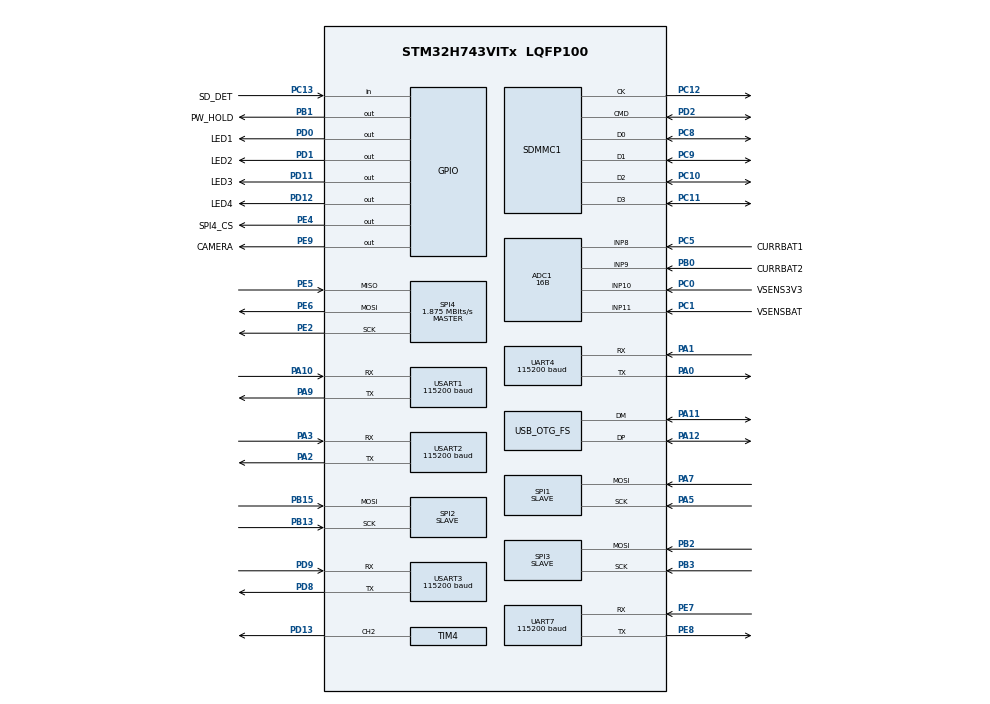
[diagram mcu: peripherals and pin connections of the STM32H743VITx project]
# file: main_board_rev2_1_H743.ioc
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ADC1.Channel-0\#ChannelRegularConversion=ADC_CHANNEL_8
ADC1.Channel-1\#ChannelRegularConversion=ADC_CHANNEL_9
ADC1.Channel-2\#ChannelRegularConversion=ADC_CHANNEL_10
ADC1.Channel-3\#ChannelRegularConversion=ADC_CHANNEL_11
ADC1.Channel-IN10=ADC_CHANNEL_10
ADC1.Channel-IN11=ADC_CHANNEL_11
ADC1.Channel-IN8=ADC_CHANNEL_8
ADC1.Channel-IN9=ADC_CHANNEL_9
ADC1.ClockPrescaler=ADC_CLOCK_ASYNC_DIV8
ADC1.ContinuousConvMode=ENABLE
ADC1.ConversionDataManagement=ADC_CONVERSIONDATA_DMA_CIRCULAR
ADC1.DiscontinuousConvMode=DISABLE
ADC1.EOCSelection=ADC_EOC_SINGLE_CONV
ADC1.EnableAnalogWatchDog1=false
ADC1.EnableAnalogWatchDog2=false
ADC1.EnableAnalogWatchDog3=false
ADC1.EnableInjectedConversion=DISABLE
ADC1.EnableRegularConversion=ENABLE
ADC1.ExternalTrigConv=ADC_SOFTWARE_START
ADC1.ExternalTrigConvEdge=ADC_EXTERNALTRIGCONVEDGE_NONE
ADC1.LeftBitShift=ADC_LEFTBITSHIFT_NONE
ADC1.LowPowerAutoWait=DISABLE
ADC1.Mode=ADC_MODE_INDEPENDENT
ADC1.NbrOfConversion=4
ADC1.OffsetNumber-0\#ChannelRegularConversion=ADC_OFFSET_NONE
ADC1.OffsetNumber-1\#ChannelRegularConversion=ADC_OFFSET_NONE
ADC1.OffsetNumber-2\#ChannelRegularConversion=ADC_OFFSET_NONE
ADC1.OffsetNumber-3\#ChannelRegularConversion=ADC_OFFSET_NONE
ADC1.OffsetSignedSaturation-0\#ChannelRegularConversion=DISABLE
ADC1.OffsetSignedSaturation-1\#ChannelRegularConversion=DISABLE
ADC1.OffsetSignedSaturation-2\#ChannelRegularConversion=DISABLE
ADC1.OffsetSignedSaturation-3\#ChannelRegularConversion=DISABLE
ADC1.Overrun=ADC_OVR_DATA_PRESERVED
ADC1.OversamplingMode=DISABLE
ADC1.Rank-0\#ChannelRegularConversion=1
ADC1.Rank-1\#ChannelRegularConversion=2
ADC1.Rank-2\#ChannelRegularConversion=3
ADC1.Rank-3\#ChannelRegularConversion=4
ADC1.Resolution=ADC_RESOLUTION_16B
ADC1.SamplingTime-0\#ChannelRegularConversion=ADC_SAMPLETIME_387CYCLES_5
ADC1.SamplingTime-1\#ChannelRegularConversion=ADC_SAMPLETIME_387CYCLES_5
ADC1.SamplingTime-2\#ChannelRegularConversion=ADC_SAMPLETIME_387CYCLES_5
ADC1.SamplingTime-3\#ChannelRegularConversion=ADC_SAMPLETIME_387CYCLES_5
ADC1.ScanConvMode=ADC_SCAN_ENABLE
ADC1.master=1
CORTEX_M7.CPU_DCache=Disabled
CORTEX_M7.CPU_ICache=Enabled
CORTEX_M7.MPU_Control=__NULL
Dma.ADC1.4.Direction=DMA_PERIPH_TO_MEMORY
Dma.ADC1.4.EventEnable=DISABLE
Dma.ADC1.4.FIFOMode=DMA_FIFOMODE_DISABLE
Dma.ADC1.4.Instance=DMA2_Stream4
Dma.ADC1.4.MemDataAlignment=DMA_MDATAALIGN_WORD
Dma.ADC1.4.MemInc=DMA_MINC_ENABLE
Dma.ADC1.4.Mode=DMA_CIRCULAR
Dma.ADC1.4.PeriphDataAlignment=DMA_PDATAALIGN_WORD
Dma.ADC1.4.PeriphInc=DMA_PINC_DISABLE
Dma.ADC1.4.Polarity=HAL_DMAMUX_REQ_GEN_RISING
Dma.ADC1.4.Priority=DMA_PRIORITY_LOW
Dma.ADC1.4.RequestNumber=1
Dma.ADC1.4.SignalID=NONE
Dma.ADC1.4.SyncEnable=DISABLE
Dma.ADC1.4.SyncPolarity=HAL_DMAMUX_SYNC_NO_EVENT
Dma.ADC1.4.SyncRequestNumber=1
Dma.ADC1.4.SyncSignalID=NONE
Dma.Request0=SPI1_RX
Dma.Request1=UART4_RX
Dma.Request2=USART2_RX
Dma.Request3=USART1_RX
Dma.Request4=ADC1
Dma.Request5=SPI3_RX
Dma.Request6=USART3_RX
Dma.Request7=SPI2_RX
Dma.Request8=UART4_TX
Dma.Request9=UART7_TX
Dma.SPI1_RX.0.Direction=DMA_PERIPH_TO_MEMORY
Dma.SPI1_RX.0.EventEnable=DISABLE
Dma.SPI1_RX.0.FIFOMode=DMA_FIFOMODE_DISABLE
Dma.SPI1_RX.0.Instance=DMA1_Stream0
Dma.SPI1_RX.0.MemDataAlignment=DMA_MDATAALIGN_BYTE
Dma.SPI1_RX.0.MemInc=DMA_MINC_ENABLE
Dma.SPI1_RX.0.Mode=DMA_CIRCULAR
Dma.SPI1_RX.0.PeriphDataAlignment=DMA_PDATAALIGN_BYTE
Dma.SPI1_RX.0.PeriphInc=DMA_PINC_DISABLE
Dma.SPI1_RX.0.Polarity=HAL_DMAMUX_REQ_GEN_RISING
Dma.SPI1_RX.0.Priority=DMA_PRIORITY_LOW
Dma.SPI1_RX.0.RequestNumber=1
Dma.SPI1_RX.0.SignalID=NONE
Dma.SPI1_RX.0.SyncEnable=DISABLE
Dma.SPI1_RX.0.SyncPolarity=HAL_DMAMUX_SYNC_NO_EVENT
Dma.SPI1_RX.0.SyncRequestNumber=1
Dma.SPI1_RX.0.SyncSignalID=NONE
Dma.SPI2_RX.7.Direction=DMA_PERIPH_TO_MEMORY
Dma.SPI2_RX.7.EventEnable=DISABLE
Dma.SPI2_RX.7.FIFOMode=DMA_FIFOMODE_DISABLE
Dma.SPI2_RX.7.Instance=DMA1_Stream1
Dma.SPI2_RX.7.MemDataAlignment=DMA_MDATAALIGN_BYTE
Dma.SPI2_RX.7.MemInc=DMA_MINC_ENABLE
Dma.SPI2_RX.7.Mode=DMA_CIRCULAR
Dma.SPI2_RX.7.PeriphDataAlignment=DMA_PDATAALIGN_BYTE
Dma.SPI2_RX.7.PeriphInc=DMA_PINC_DISABLE
Dma.SPI2_RX.7.Polarity=HAL_DMAMUX_REQ_GEN_RISING
Dma.SPI2_RX.7.Priority=DMA_PRIORITY_LOW
Dma.SPI2_RX.7.RequestNumber=1
Dma.SPI2_RX.7.SignalID=NONE
Dma.SPI2_RX.7.SyncEnable=DISABLE
Dma.SPI2_RX.7.SyncPolarity=HAL_DMAMUX_SYNC_NO_EVENT
Dma.SPI2_RX.7.SyncRequestNumber=1
Dma.SPI2_RX.7.SyncSignalID=NONE
Dma.SPI3_RX.5.Direction=DMA_PERIPH_TO_MEMORY
Dma.SPI3_RX.5.EventEnable=DISABLE
Dma.SPI3_RX.5.FIFOMode=DMA_FIFOMODE_DISABLE
Dma.SPI3_RX.5.Instance=DMA1_Stream2
Dma.SPI3_RX.5.MemDataAlignment=DMA_MDATAALIGN_BYTE
Dma.SPI3_RX.5.MemInc=DMA_MINC_ENABLE
Dma.SPI3_RX.5.Mode=DMA_CIRCULAR
Dma.SPI3_RX.5.PeriphDataAlignment=DMA_PDATAALIGN_BYTE
Dma.SPI3_RX.5.PeriphInc=DMA_PINC_DISABLE
Dma.SPI3_RX.5.Polarity=HAL_DMAMUX_REQ_GEN_RISING
Dma.SPI3_RX.5.Priority=DMA_PRIORITY_LOW
Dma.SPI3_RX.5.RequestNumber=1
Dma.SPI3_RX.5.SignalID=NONE
Dma.SPI3_RX.5.SyncEnable=DISABLE
Dma.SPI3_RX.5.SyncPolarity=HAL_DMAMUX_SYNC_NO_EVENT
Dma.SPI3_RX.5.SyncRequestNumber=1
Dma.SPI3_RX.5.SyncSignalID=NONE
Dma.UART4_RX.1.Direction=DMA_PERIPH_TO_MEMORY
Dma.UART4_RX.1.EventEnable=DISABLE
Dma.UART4_RX.1.FIFOMode=DMA_FIFOMODE_DISABLE
Dma.UART4_RX.1.Instance=DMA1_Stream3
Dma.UART4_RX.1.MemDataAlignment=DMA_MDATAALIGN_BYTE
Dma.UART4_RX.1.MemInc=DMA_MINC_ENABLE
Dma.UART4_RX.1.Mode=DMA_CIRCULAR
Dma.UART4_RX.1.PeriphDataAlignment=DMA_PDATAALIGN_BYTE
Dma.UART4_RX.1.PeriphInc=DMA_PINC_DISABLE
Dma.UART4_RX.1.Polarity=HAL_DMAMUX_REQ_GEN_RISING
Dma.UART4_RX.1.Priority=DMA_PRIORITY_LOW
Dma.UART4_RX.1.RequestNumber=1
Dma.UART4_RX.1.SignalID=NONE
Dma.UART4_RX.1.SyncEnable=DISABLE
Dma.UART4_RX.1.SyncPolarity=HAL_DMAMUX_SYNC_NO_EVENT
Dma.UART4_RX.1.SyncRequestNumber=1
Dma.UART4_RX.1.SyncSignalID=NONE
Dma.UART4_TX.8.Direction=DMA_MEMORY_TO_PERIPH
Dma.UART4_TX.8.EventEnable=DISABLE
Dma.UART4_TX.8.FIFOMode=DMA_FIFOMODE_DISABLE
Dma.UART4_TX.8.Instance=DMA2_Stream0
Dma.UART4_TX.8.MemDataAlignment=DMA_MDATAALIGN_BYTE
Dma.UART4_TX.8.MemInc=DMA_MINC_ENABLE
Dma.UART4_TX.8.Mode=DMA_NORMAL
Dma.UART4_TX.8.PeriphDataAlignment=DMA_PDATAALIGN_BYTE
Dma.UART4_TX.8.PeriphInc=DMA_PINC_DISABLE
Dma.UART4_TX.8.Polarity=HAL_DMAMUX_REQ_GEN_RISING
Dma.UART4_TX.8.Priority=DMA_PRIORITY_LOW
Dma.UART4_TX.8.RequestNumber=1
Dma.UART4_TX.8.SignalID=NONE
Dma.UART4_TX.8.SyncEnable=DISABLE
Dma.UART4_TX.8.SyncPolarity=HAL_DMAMUX_SYNC_NO_EVENT
Dma.UART4_TX.8.SyncRequestNumber=1
Dma.UART4_TX.8.SyncSignalID=NONE
Dma.UART7_TX.9.Direction=DMA_MEMORY_TO_PERIPH
Dma.UART7_TX.9.EventEnable=DISABLE
Dma.UART7_TX.9.FIFOMode=DMA_FIFOMODE_DISABLE
Dma.UART7_TX.9.Instance=DMA2_Stream1
Dma.UART7_TX.9.MemDataAlignment=DMA_MDATAALIGN_BYTE
Dma.UART7_TX.9.MemInc=DMA_MINC_ENABLE
Dma.UART7_TX.9.Mode=DMA_NORMAL
Dma.UART7_TX.9.PeriphDataAlignment=DMA_PDATAALIGN_BYTE
Dma.UART7_TX.9.PeriphInc=DMA_PINC_DISABLE
Dma.UART7_TX.9.Polarity=HAL_DMAMUX_REQ_GEN_RISING
Dma.UART7_TX.9.Priority=DMA_PRIORITY_LOW
Dma.UART7_TX.9.RequestNumber=1
Dma.UART7_TX.9.SignalID=NONE
Dma.UART7_TX.9.SyncEnable=DISABLE
Dma.UART7_TX.9.SyncPolarity=HAL_DMAMUX_SYNC_NO_EVENT
Dma.UART7_TX.9.SyncRequestNumber=1
Dma.UART7_TX.9.SyncSignalID=NONE
Dma.USART1_RX.3.Direction=DMA_PERIPH_TO_MEMORY
Dma.USART1_RX.3.EventEnable=DISABLE
Dma.USART1_RX.3.FIFOMode=DMA_FIFOMODE_DISABLE
Dma.USART1_RX.3.Instance=DMA1_Stream5
Dma.USART1_RX.3.MemDataAlignment=DMA_MDATAALIGN_BYTE
Dma.USART1_RX.3.MemInc=DMA_MINC_ENABLE
Dma.USART1_RX.3.Mode=DMA_NORMAL
Dma.USART1_RX.3.PeriphDataAlignment=DMA_PDATAALIGN_BYTE
Dma.USART1_RX.3.PeriphInc=DMA_PINC_DISABLE
Dma.USART1_RX.3.Polarity=HAL_DMAMUX_REQ_GEN_RISING
Dma.USART1_RX.3.Priority=DMA_PRIORITY_LOW
Dma.USART1_RX.3.RequestNumber=1
Dma.USART1_RX.3.SignalID=NONE
Dma.USART1_RX.3.SyncEnable=DISABLE
Dma.USART1_RX.3.SyncPolarity=HAL_DMAMUX_SYNC_NO_EVENT
Dma.USART1_RX.3.SyncRequestNumber=1
Dma.USART1_RX.3.SyncSignalID=NONE
Dma.USART2_RX.2.Direction=DMA_PERIPH_TO_MEMORY
Dma.USART2_RX.2.EventEnable=DISABLE
Dma.USART2_RX.2.FIFOMode=DMA_FIFOMODE_DISABLE
Dma.USART2_RX.2.Instance=DMA1_Stream6
Dma.USART2_RX.2.MemDataAlignment=DMA_MDATAALIGN_BYTE
Dma.USART2_RX.2.MemInc=DMA_MINC_ENABLE
Dma.USART2_RX.2.Mode=DMA_NORMAL
Dma.USART2_RX.2.PeriphDataAlignment=DMA_PDATAALIGN_BYTE
Dma.USART2_RX.2.PeriphInc=DMA_PINC_DISABLE
Dma.USART2_RX.2.Polarity=HAL_DMAMUX_REQ_GEN_RISING
Dma.USART2_RX.2.Priority=DMA_PRIORITY_LOW
Dma.USART2_RX.2.RequestNumber=1
Dma.USART2_RX.2.SignalID=NONE
Dma.USART2_RX.2.SyncEnable=DISABLE
Dma.USART2_RX.2.SyncPolarity=HAL_DMAMUX_SYNC_NO_EVENT
Dma.USART2_RX.2.SyncRequestNumber=1
Dma.USART2_RX.2.SyncSignalID=NONE
Dma.USART3_RX.6.Direction=DMA_PERIPH_TO_MEMORY
Dma.USART3_RX.6.EventEnable=DISABLE
Dma.USART3_RX.6.FIFOMode=DMA_FIFOMODE_DISABLE
Dma.USART3_RX.6.Instance=DMA1_Stream7
Dma.USART3_RX.6.MemDataAlignment=DMA_MDATAALIGN_BYTE
Dma.USART3_RX.6.MemInc=DMA_MINC_ENABLE
Dma.USART3_RX.6.Mode=DMA_NORMAL
Dma.USART3_RX.6.PeriphDataAlignment=DMA_PDATAALIGN_BYTE
Dma.USART3_RX.6.PeriphInc=DMA_PINC_DISABLE
Dma.USART3_RX.6.Polarity=HAL_DMAMUX_REQ_GEN_RISING
Dma.USART3_RX.6.Priority=DMA_PRIORITY_LOW
Dma.USART3_RX.6.RequestNumber=1
Dma.USART3_RX.6.SignalID=NONE
Dma.USART3_RX.6.SyncEnable=DISABLE
Dma.USART3_RX.6.SyncPolarity=HAL_DMAMUX_SYNC_NO_EVENT
Dma.USART3_RX.6.SyncRequestNumber=1
Dma.USART3_RX.6.SyncSignalID=NONE
FATFS.BSP.number=1
FATFS.SD_BSP_CODE=0
FATFS.USE_DMA_CODE_SD=1
FATFS._CODE_PAGE=850
FATFS._FS_EXFAT=0
FATFS._FS_LOCK=2
FATFS._FS_MINIMIZE=0
FATFS._FS_NOFSINFO=0
FATFS._FS_NORTC=0
FATFS._FS_READONLY=0
FATFS._FS_REENTRANT=1
FATFS._FS_RPATH=0
FATFS._FS_TIMEOUT=1000
FATFS._FS_TINY=0
FATFS._HSD=hsd1
FATFS._LFN_UNICODE=0
FATFS._MAX_LFN=255
FATFS._MAX_SS=512
FATFS._MIN_SS=512
FATFS._MULTI_PARTITION=0
FATFS._STRF_ENCODE=3
FATFS._USE_CHMOD=0
FATFS._USE_EXPAND=0
FATFS._USE_FASTSEEK=1
FATFS._USE_FIND=1
FATFS._USE_FORWARD=0
FATFS._USE_LABEL=0
FATFS._USE_LFN=0
FATFS._USE_MKFS=1
FATFS._USE_MUTEX=0
FATFS._USE_STRFUNC=2
FATFS._USE_TRIM=0
FATFS._VOLUMES=1
FATFS0.BSP.STBoard=false
FATFS0.BSP.api=Unknown
FATFS0.BSP.i2caddr=0
FATFS0.BSP.instance=PC13
FATFS0.BSP.ip=GPIO
FATFS0.BSP.mode=Input
FATFS0.BSP.name=Detect_SDIO
FATFS0.BSP.solution=PC13
FREERTOS.HEAP_NUMBER=4
FREERTOS.INCLUDE_eTaskGetState=1
FREERTOS.INCLUDE_pcTaskGetTaskName=0
FREERTOS.INCLUDE_uxTaskGetStackHighWaterMark=1
FREERTOS.INCLUDE_uxTaskGetStackHighWaterMark2=0
FREERTOS.INCLUDE_uxTaskPriorityGet=1
FREERTOS.INCLUDE_vTaskCleanUpResources=0
FREERTOS.INCLUDE_vTaskDelay=1
FREERTOS.INCLUDE_vTaskDelayUntil=1
FREERTOS.INCLUDE_vTaskDelete=1
FREERTOS.INCLUDE_vTaskPrioritySet=1
FREERTOS.INCLUDE_vTaskSuspend=1
FREERTOS.INCLUDE_xEventGroupSetBitFromISR=0
FREERTOS.INCLUDE_xQueueGetMutexHolder=1
FREERTOS.INCLUDE_xSemaphoreGetMutexHolder=0
FREERTOS.INCLUDE_xTaskAbortDelay=0
FREERTOS.INCLUDE_xTaskGetCurrentTaskHandle=0
FREERTOS.INCLUDE_xTaskGetHandle=0
FREERTOS.INCLUDE_xTaskGetSchedulerState=1
FREERTOS.INCLUDE_xTaskResumeFromISR=1
FREERTOS.INCLUDE_xTimerPendFunctionCall=1
FREERTOS.Tasks01=defaultTask,8,128,StartDefaultTask,Default,NULL,Dynamic,NULL,NULL;task_state_est,43,2048,vTaskStateEst,As external,NULL,Static,task_state_estBuffer,task_state_estControlBlock;task_controller,39,2048,vTaskController,As external,NULL,Static,task_controllerBuffer,task_controllerControlBlock;task_sens_read,47,512,vTaskSensRead,As external,NULL,Static,task_sens_readBuffer,task_sens_readControlBlock;task_sd_card,41,1024,vTaskSdCard,As external,NULL,Static,task_sd_cardBuffer,task_sd_cardControlBlock;task_motor_cont,38,512,vTaskMotorCont,As external,NULL,Static,task_motor_contBuffer,task_motor_contControlBlock;task_fsm,45,512,vTaskFsm,As external,NULL,Static,task_fsmBuffer,task_fsmControlBlock;task_gps,46,512,vTaskGps,As external,NULL,Static,task_gpsBuffer,task_gpsControlBlock;task_battery,40,512,vTaskBattery,As external,NULL,Static,task_batteryBuffer,task_batteryControlBlock;task_xbee,44,512,vTaskXbee,As external,NULL,Static,task_xbeeBuffer,task_xbeeControlBlock;task_peripherals,42,128,vTaskPeripherals,As external,NULL,Static,task_peripheralsBuffer,task_peripheralsControlBlock
FREERTOS.configCHECK_FOR_STACK_OVERFLOW=0
FREERTOS.configENABLE_BACKWARD_COMPATIBILITY=1
FREERTOS.configENABLE_FPU=1
FREERTOS.configGENERATE_RUN_TIME_STATS=0
FREERTOS.configIDLE_SHOULD_YIELD=1
FREERTOS.configLIBRARY_LOWEST_INTERRUPT_PRIORITY=15
FREERTOS.configLIBRARY_MAX_SYSCALL_INTERRUPT_PRIORITY=5
FREERTOS.configMAX_CO_ROUTINE_PRIORITIES=2
FREERTOS.configMAX_TASK_NAME_LEN=20
FREERTOS.configMINIMAL_STACK_SIZE=128
FREERTOS.configQUEUE_REGISTRY_SIZE=8
FREERTOS.configRECORD_STACK_HIGH_ADDRESS=0
FREERTOS.configTICK_RATE_HZ=1000
FREERTOS.configTIMER_QUEUE_LENGTH=10
FREERTOS.configTIMER_TASK_PRIORITY=2
FREERTOS.configTIMER_TASK_STACK_DEPTH=256
FREERTOS.configTOTAL_HEAP_SIZE=60720
FREERTOS.configUSE_APPLICATION_TASK_TAG=0
FREERTOS.configUSE_COUNTING_SEMAPHORES=1
FREERTOS.configUSE_CO_ROUTINES=0
FREERTOS.configUSE_DAEMON_TASK_STARTUP_HOOK=0
FREERTOS.configUSE_IDLE_HOOK=0
FREERTOS.configUSE_MALLOC_FAILED_HOOK=0
FREERTOS.configUSE_MUTEXES=1
FREERTOS.configUSE_NEWLIB_REENTRANT=0
FREERTOS.configUSE_POSIX_ERRNO=0
FREERTOS.configUSE_PREEMPTION=1
FREERTOS.configUSE_RECURSIVE_MUTEXES=1
FREERTOS.configUSE_STATS_FORMATTING_FUNCTIONS=0
FREERTOS.configUSE_TASK_NOTIFICATIONS=1
FREERTOS.configUSE_TICKLESS_IDLE=0
FREERTOS.configUSE_TICK_HOOK=0
FREERTOS.configUSE_TRACE_FACILITY=1
FREERTOS.copyHeapFile=1
Mcu.Family=STM32H7
Mcu.Name=STM32H743VITx
Mcu.Package=LQFP100
NVIC.DMA1_Stream0_IRQn=true\:5\:0\:true\:false\:true\:true\:false\:true
NVIC.DMA1_Stream1_IRQn=true\:5\:0\:true\:false\:true\:true\:false\:true
NVIC.DMA1_Stream2_IRQn=true\:5\:0\:true\:false\:true\:true\:false\:true
NVIC.DMA1_Stream3_IRQn=true\:5\:0\:true\:false\:true\:true\:false\:true
NVIC.DMA1_Stream5_IRQn=true\:5\:0\:true\:false\:true\:true\:false\:true
NVIC.DMA1_Stream6_IRQn=true\:5\:0\:true\:false\:true\:true\:false\:true
NVIC.DMA1_Stream7_IRQn=true\:0\:0\:false\:false\:true\:true\:false\:true
NVIC.DMA2_Stream0_IRQn=true\:0\:0\:false\:false\:true\:true\:false\:true
NVIC.DMA2_Stream1_IRQn=true\:0\:0\:false\:false\:true\:true\:false\:true
NVIC.DMA2_Stream4_IRQn=true\:5\:0\:true\:false\:true\:false\:false\:true
NVIC.OTG_FS_IRQn=true\:5\:0\:true\:false\:true\:true\:false\:true
NVIC.PriorityGroup=NVIC_PRIORITYGROUP_4
NVIC.SDMMC1_IRQn=true\:5\:0\:true\:false\:true\:true\:true\:true
NVIC.SPI1_IRQn=true\:5\:0\:true\:false\:true\:true\:true\:true
NVIC.SPI2_IRQn=true\:5\:0\:true\:false\:true\:true\:true\:true
NVIC.SPI3_IRQn=true\:5\:0\:true\:false\:true\:true\:true\:true
NVIC.TIM1_UP_IRQn=true\:0\:0\:false\:false\:true\:false\:true\:true
NVIC.TimeBase=TIM1_UP_IRQn
NVIC.TimeBaseIP=TIM1
NVIC.UART4_IRQn=true\:0\:0\:false\:false\:true\:false\:true\:true
NVIC.UART7_IRQn=true\:0\:0\:false\:false\:true\:false\:true\:true
PA0.Mode=Asynchronous
PA0.Signal=UART4_TX
PA1.Mode=Asynchronous
PA1.Signal=UART4_RX
PA10.Mode=Asynchronous
PA10.Signal=USART1_RX
PA11.Mode=Device_Only
PA11.Signal=USB_OTG_FS_DM
PA12.Mode=Device_Only
PA12.Signal=USB_OTG_FS_DP
PA13\ (JTMS/SWDIO).Mode=Serial_Wire
PA13\ (JTMS/SWDIO).Signal=DEBUG_JTMS-SWDIO
PA14\ (JTCK/SWCLK).Mode=Serial_Wire
PA14\ (JTCK/SWCLK).Signal=DEBUG_JTCK-SWCLK
PA15\ (JTDI).Signal=SPI1_NSS
PA2.Mode=Asynchronous
PA2.Signal=USART2_TX
PA3.Mode=Asynchronous
PA3.Signal=USART2_RX
PA4.Signal=SPI3_NSS
PA5.GPIO_Speed=GPIO_SPEED_FREQ_MEDIUM
PA5.Mode=RX_Only_Simplex_Unidirect_Slave
PA5.Signal=SPI1_SCK
PA7.GPIO_Speed=GPIO_SPEED_FREQ_MEDIUM
PA7.Mode=RX_Only_Simplex_Unidirect_Slave
PA7.Signal=SPI1_MOSI
PA9.Mode=Asynchronous
PA9.Signal=USART1_TX
PB0.GPIO_Label=CURRBAT2
PB0.Signal=ADCx_INP9
PB1.GPIO_Label=PW_HOLD
PB1.Signal=GPIO_Output
PB12.Signal=SPI2_NSS
PB13.GPIO_Speed=GPIO_SPEED_FREQ_VERY_HIGH
PB13.Mode=RX_Only_Simplex_Unidirect_Slave
PB13.Signal=SPI2_SCK
PB15.GPIO_Speed=GPIO_SPEED_FREQ_VERY_HIGH
PB15.Mode=RX_Only_Simplex_Unidirect_Slave
PB15.Signal=SPI2_MOSI
PB2.GPIO_Speed=GPIO_SPEED_FREQ_MEDIUM
PB2.Mode=RX_Only_Simplex_Unidirect_Slave
PB2.Signal=SPI3_MOSI
PB3\ (JTDO/TRACESWO).GPIO_Speed=GPIO_SPEED_FREQ_MEDIUM
PB3\ (JTDO/TRACESWO).Mode=RX_Only_Simplex_Unidirect_Slave
PB3\ (JTDO/TRACESWO).Signal=SPI3_SCK
PC0.GPIO_Label=VSENS3V3
PC0.Signal=ADCx_INP10
PC1.GPIO_Label=VSENSBAT
PC1.Signal=ADCx_INP11
PC10.Mode=SD_4_bits_Wide_bus
PC10.Signal=SDMMC1_D2
PC11.Mode=SD_4_bits_Wide_bus
PC11.Signal=SDMMC1_D3
PC12.Mode=SD_4_bits_Wide_bus
PC12.Signal=SDMMC1_CK
PC13.GPIO_Label=SD_DET
PC13.Signal=GPIO_Input
PC5.GPIO_Label=CURRBAT1
PC5.Signal=ADCx_INP8
PC8.Mode=SD_4_bits_Wide_bus
PC8.Signal=SDMMC1_D0
PC9.Mode=SD_4_bits_Wide_bus
PC9.Signal=SDMMC1_D1
PD0.GPIO_Label=LED1
PD0.Signal=GPIO_Output
PD1.GPIO_Label=LED2
PD1.Signal=GPIO_Output
PD11.GPIO_Label=LED3
PD11.Signal=GPIO_Output
PD12.GPIO_Label=LED4
PD12.Signal=GPIO_Output
PD13.Signal=S_TIM4_CH2
PD2.Mode=SD_4_bits_Wide_bus
PD2.Signal=SDMMC1_CMD
PD8.Mode=Asynchronous
PD8.Signal=USART3_TX
PD9.Mode=Asynchronous
PD9.Signal=USART3_RX
PE2.Mode=Full_Duplex_Master
PE2.Signal=SPI4_SCK
PE4.GPIO_Label=SPI4_CS
PE4.Signal=GPIO_Output
PE5.Mode=Full_Duplex_Master
PE5.Signal=SPI4_MISO
PE6.Mode=Full_Duplex_Master
PE6.Signal=SPI4_MOSI
PE7.Mode=Asynchronous
PE7.Signal=UART7_RX
PE8.Mode=Asynchronous
PE8.Signal=UART7_TX
PE9.GPIO_Label=CAMERA
PE9.Signal=GPIO_Output
PH0-OSC_IN\ (PH0).Mode=HSE-External-Oscillator
PH0-OSC_IN\ (PH0).Signal=RCC_OSC_IN
PH1-OSC_OUT\ (PH1).Mode=HSE-External-Oscillator
PH1-OSC_OUT\ (PH1).Signal=RCC_OSC_OUT
ProjectManager.HeapSize=0x400
ProjectManager.StackSize=0x800
ProjectManager.TargetToolchain=STM32CubeIDE
RCC.ADCFreq_Value=150000000
RCC.APB1Freq_Value=120000000
RCC.APB2Freq_Value=120000000
RCC.APB3Freq_Value=120000000
RCC.APB4Freq_Value=120000000
RCC.CortexFreq_Value=480000000
RCC.D1PPRE=RCC_APB3_DIV2
RCC.D2PPRE1=RCC_APB1_DIV2
RCC.D2PPRE2=RCC_APB2_DIV2
RCC.D3PPRE=RCC_APB4_DIV2
RCC.DIVM1=1
RCC.DIVM2=1
RCC.DIVN1=120
RCC.DIVN2=18
RCC.DIVP2=1
RCC.DIVQ1=8
RCC.HCLKFreq_Value=240000000
RCC.HPRE=RCC_HCLK_DIV2
RCC.HSE_VALUE=8000000
RCC.PLL1_VCI_Range=RCC_PLL1VCIRANGE_3
RCC.PLL2FRACN=6144
RCC.PLL3FRACN=0
RCC.PLLFRACN=0
RCC.PLLSourceVirtual=RCC_PLLSOURCE_HSE
RCC.SYSCLKFreq_VALUE=480000000
RCC.SYSCLKSource=RCC_SYSCLKSOURCE_PLLCLK
RCC.USBCLockSelection=RCC_USBCLKSOURCE_HSI48
RCC.USBFreq_Value=48000000
SDMMC1.ClockDiv=0
SDMMC1.ClockEdge=SDMMC_CLOCK_EDGE_RISING
SDMMC1.ClockPowerSave=SDMMC_CLOCK_POWER_SAVE_DISABLE
SDMMC1.HardwareFlowControl=SDMMC_HARDWARE_FLOW_CONTROL_DISABLE
SDMMC1.TransceiverPresent=SDMMC_TRANSCEIVER_NOT_PRESENT
SH.ADCx_INP10.0=ADC1_INP10,IN10-Single-Ended
SH.ADCx_INP11.0=ADC1_INP11,IN11-Single-Ended
SH.ADCx_INP8.0=ADC1_INP8,IN8-Single-Ended
SH.ADCx_INP9.0=ADC1_INP9,IN9-Single-Ended
SH.S_TIM4_CH2.0=TIM4_CH2,PWM Generation2 CH2
SPI1.CLKPhase=SPI_PHASE_1EDGE
SPI1.CLKPolarity=SPI_POLARITY_LOW
SPI1.CRCCalculation=SPI_CRCCALCULATION_DISABLE
SPI1.DataSize=SPI_DATASIZE_8BIT
SPI1.Direction=SPI_DIRECTION_2LINES_RXONLY
SPI1.FifoThreshold=SPI_FIFO_THRESHOLD_01DATA
SPI1.FirstBit=SPI_FIRSTBIT_MSB
SPI1.IOSwap=SPI_IO_SWAP_DISABLE
SPI1.MasterInterDataIdleness=SPI_MASTER_INTERDATA_IDLENESS_00CYCLE
SPI1.MasterKeepIOState=SPI_MASTER_KEEP_IO_STATE_DISABLE
SPI1.MasterReceiverAutoSusp=SPI_MASTER_RX_AUTOSUSP_DISABLE
SPI1.MasterSSIdleness=SPI_MASTER_SS_IDLENESS_00CYCLE
SPI1.Mode=SPI_MODE_SLAVE
SPI1.NSS=SPI_NSS_SOFT
SPI1.NSSPolarity=SPI_NSS_POLARITY_LOW
SPI1.RxCRCInitializationPattern=SPI_CRC_INITIALIZATION_ALL_ZERO_PATTERN
SPI1.TIMode=SPI_TIMODE_DISABLE
SPI1.TxCRCInitializationPattern=SPI_CRC_INITIALIZATION_ALL_ZERO_PATTERN
SPI1.VirtualType=VM_SLAVE
SPI2.CLKPhase=SPI_PHASE_1EDGE
SPI2.CLKPolarity=SPI_POLARITY_LOW
SPI2.CRCCalculation=SPI_CRCCALCULATION_DISABLE
SPI2.DataSize=SPI_DATASIZE_8BIT
SPI2.Direction=SPI_DIRECTION_2LINES_RXONLY
SPI2.FifoThreshold=SPI_FIFO_THRESHOLD_01DATA
SPI2.FirstBit=SPI_FIRSTBIT_MSB
SPI2.IOSwap=SPI_IO_SWAP_DISABLE
SPI2.MasterInterDataIdleness=SPI_MASTER_INTERDATA_IDLENESS_00CYCLE
SPI2.MasterKeepIOState=SPI_MASTER_KEEP_IO_STATE_DISABLE
SPI2.MasterReceiverAutoSusp=SPI_MASTER_RX_AUTOSUSP_DISABLE
SPI2.MasterSSIdleness=SPI_MASTER_SS_IDLENESS_00CYCLE
SPI2.Mode=SPI_MODE_SLAVE
SPI2.NSS=SPI_NSS_SOFT
SPI2.NSSPolarity=SPI_NSS_POLARITY_LOW
SPI2.RxCRCInitializationPattern=SPI_CRC_INITIALIZATION_ALL_ZERO_PATTERN
SPI2.TIMode=SPI_TIMODE_DISABLE
SPI2.TxCRCInitializationPattern=SPI_CRC_INITIALIZATION_ALL_ZERO_PATTERN
SPI2.VirtualType=VM_SLAVE
SPI3.CLKPhase=SPI_PHASE_1EDGE
SPI3.CLKPolarity=SPI_POLARITY_LOW
SPI3.CRCCalculation=SPI_CRCCALCULATION_DISABLE
SPI3.DataSize=SPI_DATASIZE_8BIT
SPI3.Direction=SPI_DIRECTION_2LINES_RXONLY
SPI3.FifoThreshold=SPI_FIFO_THRESHOLD_01DATA
SPI3.FirstBit=SPI_FIRSTBIT_MSB
SPI3.IOSwap=SPI_IO_SWAP_DISABLE
SPI3.MasterInterDataIdleness=SPI_MASTER_INTERDATA_IDLENESS_00CYCLE
SPI3.MasterKeepIOState=SPI_MASTER_KEEP_IO_STATE_DISABLE
SPI3.MasterReceiverAutoSusp=SPI_MASTER_RX_AUTOSUSP_DISABLE
SPI3.MasterSSIdleness=SPI_MASTER_SS_IDLENESS_00CYCLE
SPI3.Mode=SPI_MODE_SLAVE
SPI3.NSS=SPI_NSS_SOFT
SPI3.NSSPolarity=SPI_NSS_POLARITY_LOW
SPI3.RxCRCInitializationPattern=SPI_CRC_INITIALIZATION_ALL_ZERO_PATTERN
SPI3.TIMode=SPI_TIMODE_DISABLE
SPI3.TxCRCInitializationPattern=SPI_CRC_INITIALIZATION_ALL_ZERO_PATTERN
SPI3.VirtualType=VM_SLAVE
SPI4.BaudRatePrescaler=SPI_BAUDRATEPRESCALER_64
SPI4.CLKPhase=SPI_PHASE_1EDGE
SPI4.CLKPolarity=SPI_POLARITY_LOW
SPI4.CRCCalculation=SPI_CRCCALCULATION_DISABLE
SPI4.CalculateBaudRate=1.875 MBits/s
SPI4.DataSize=SPI_DATASIZE_8BIT
SPI4.Direction=SPI_DIRECTION_2LINES
SPI4.FifoThreshold=SPI_FIFO_THRESHOLD_01DATA
SPI4.FirstBit=SPI_FIRSTBIT_MSB
SPI4.IOSwap=SPI_IO_SWAP_DISABLE
SPI4.MasterInterDataIdleness=SPI_MASTER_INTERDATA_IDLENESS_00CYCLE
SPI4.MasterKeepIOState=SPI_MASTER_KEEP_IO_STATE_DISABLE
SPI4.MasterReceiverAutoSusp=SPI_MASTER_RX_AUTOSUSP_DISABLE
SPI4.MasterSSIdleness=SPI_MASTER_SS_IDLENESS_00CYCLE
SPI4.Mode=SPI_MODE_MASTER
SPI4.NSS=SPI_NSS_SOFT
SPI4.NSSPMode=SPI_NSS_PULSE_ENABLE
SPI4.NSSPolarity=SPI_NSS_POLARITY_LOW
SPI4.RxCRCInitializationPattern=SPI_CRC_INITIALIZATION_ALL_ZERO_PATTERN
SPI4.TIMode=SPI_TIMODE_DISABLE
SPI4.TxCRCInitializationPattern=SPI_CRC_INITIALIZATION_ALL_ZERO_PATTERN
SPI4.VirtualType=VM_MASTER
TIM4.Channel-PWM\ Generation2\ CH2=TIM_CHANNEL_2
TIM4.Period=250
TIM4.Prescaler=240
TIM4.Pulse-PWM\ Generation2\ CH2=125
UART4.AutoBaudRateEnableParam=UART_ADVFEATURE_AUTOBAUDRATE_DISABLE
UART4.BaudRate=115200
UART4.ClockPrescaler=PRESCALER_DIV1
UART4.DMADisableonRxErrorParam=UART_ADVFEATURE_DMA_ENABLEONRXERROR
UART4.DataInvertParam=UART_ADVFEATURE_DATAINV_DISABLE
UART4.FIFOMode=FIFOMODE_DISABLE
UART4.MSBFirstParam=UART_ADVFEATURE_MSBFIRST_DISABLE
UART4.Mode=MODE_TX_RX
UART4.OneBitSampling=UART_ONE_BIT_SAMPLE_DISABLE
UART4.OverSampling=UART_OVERSAMPLING_16
UART4.OverrunDisableParam=UART_ADVFEATURE_OVERRUN_ENABLE
UART4.Parity=PARITY_NONE
UART4.RXFIFOThreshold=RXFIFO_THRESHOLD_1EIGHTHFULL
UART4.RxPinLevelInvertParam=UART_ADVFEATURE_RXINV_DISABLE
UART4.StopBits=UART_STOPBITS_1
UART4.SwapParam=UART_ADVFEATURE_SWAP_DISABLE
UART4.TXFIFOThreshold=TXFIFO_THRESHOLD_1EIGHTHFULL
UART4.TxPinLevelInvertParam=UART_ADVFEATURE_TXINV_DISABLE
UART4.WordLength=WORDLENGTH_8B
UART7.AutoBaudRateEnableParam=UART_ADVFEATURE_AUTOBAUDRATE_DISABLE
UART7.BaudRate=115200
UART7.ClockPrescaler=PRESCALER_DIV1
UART7.DMADisableonRxErrorParam=UART_ADVFEATURE_DMA_ENABLEONRXERROR
UART7.DataInvertParam=UART_ADVFEATURE_DATAINV_DISABLE
UART7.FIFOMode=FIFOMODE_DISABLE
UART7.MSBFirstParam=UART_ADVFEATURE_MSBFIRST_DISABLE
UART7.Mode=MODE_TX_RX
UART7.OneBitSampling=UART_ONE_BIT_SAMPLE_DISABLE
UART7.OverSampling=UART_OVERSAMPLING_16
UART7.OverrunDisableParam=UART_ADVFEATURE_OVERRUN_ENABLE
UART7.Parity=PARITY_NONE
UART7.RXFIFOThreshold=RXFIFO_THRESHOLD_1EIGHTHFULL
UART7.RxPinLevelInvertParam=UART_ADVFEATURE_RXINV_DISABLE
UART7.StopBits=UART_STOPBITS_1
UART7.SwapParam=UART_ADVFEATURE_SWAP_ENABLE
UART7.TXFIFOThreshold=TXFIFO_THRESHOLD_1EIGHTHFULL
UART7.TxPinLevelInvertParam=UART_ADVFEATURE_TXINV_DISABLE
UART7.WordLength=WORDLENGTH_8B
USART1.AutoBaudRateEnableParam=UART_ADVFEATURE_AUTOBAUDRATE_DISABLE
USART1.BaudRate=115200
USART1.ClockPrescaler=PRESCALER_DIV1
USART1.DMADisableonRxErrorParam=ADVFEATURE_DMA_ENABLEONRXERROR
USART1.DataInvertParam=ADVFEATURE_DATAINV_DISABLE
USART1.FIFOMode=FIFOMODE_DISABLE
USART1.MSBFirstParam=ADVFEATURE_MSBFIRST_DISABLE
USART1.Mode=MODE_TX_RX
USART1.OneBitSampling=UART_ONE_BIT_SAMPLE_DISABLE
USART1.OverSampling=UART_OVERSAMPLING_16
USART1.OverrunDisableParam=ADVFEATURE_OVERRUN_ENABLE
USART1.Parity=PARITY_NONE
USART1.RXFIFOThreshold=RXFIFO_THRESHOLD_1EIGHTHFULL
USART1.RxPinLevelInvertParam=ADVFEATURE_RXINV_DISABLE
USART1.StopBits=STOPBITS_1
USART1.SwapParam=ADVFEATURE_SWAP_DISABLE
USART1.TXFIFOThreshold=TXFIFO_THRESHOLD_1EIGHTHFULL
USART1.TxPinLevelInvertParam=ADVFEATURE_TXINV_DISABLE
USART1.VirtualMode-Asynchronous=VM_ASYNC
USART1.WordLength=WORDLENGTH_8B
USART2.AutoBaudRateEnableParam=UART_ADVFEATURE_AUTOBAUDRATE_DISABLE
USART2.BaudRate=115200
USART2.ClockPrescaler=PRESCALER_DIV1
USART2.DMADisableonRxErrorParam=ADVFEATURE_DMA_ENABLEONRXERROR
USART2.DataInvertParam=ADVFEATURE_DATAINV_DISABLE
USART2.FIFOMode=FIFOMODE_DISABLE
USART2.MSBFirstParam=ADVFEATURE_MSBFIRST_DISABLE
USART2.Mode=MODE_TX_RX
USART2.OneBitSampling=UART_ONE_BIT_SAMPLE_DISABLE
USART2.OverSampling=UART_OVERSAMPLING_16
USART2.OverrunDisableParam=ADVFEATURE_OVERRUN_ENABLE
USART2.Parity=PARITY_NONE
USART2.RXFIFOThreshold=RXFIFO_THRESHOLD_1EIGHTHFULL
USART2.RxPinLevelInvertParam=ADVFEATURE_RXINV_DISABLE
USART2.StopBits=STOPBITS_1
USART2.SwapParam=ADVFEATURE_SWAP_DISABLE
USART2.TXFIFOThreshold=TXFIFO_THRESHOLD_1EIGHTHFULL
USART2.TxPinLevelInvertParam=ADVFEATURE_TXINV_DISABLE
USART2.VirtualMode-Asynchronous=VM_ASYNC
USART2.WordLength=WORDLENGTH_8B
USART3.AutoBaudRateEnableParam=UART_ADVFEATURE_AUTOBAUDRATE_DISABLE
USART3.BaudRate=115200
USART3.ClockPrescaler=PRESCALER_DIV1
USART3.DMADisableonRxErrorParam=ADVFEATURE_DMA_ENABLEONRXERROR
USART3.DataInvertParam=ADVFEATURE_DATAINV_DISABLE
USART3.FIFOMode=FIFOMODE_DISABLE
USART3.MSBFirstParam=ADVFEATURE_MSBFIRST_DISABLE
USART3.Mode=MODE_TX_RX
USART3.OneBitSampling=UART_ONE_BIT_SAMPLE_DISABLE
USART3.OverSampling=UART_OVERSAMPLING_16
USART3.OverrunDisableParam=ADVFEATURE_OVERRUN_ENABLE
USART3.Parity=PARITY_NONE
USART3.RXFIFOThreshold=RXFIFO_THRESHOLD_1EIGHTHFULL
USART3.RxPinLevelInvertParam=ADVFEATURE_RXINV_DISABLE
USART3.StopBits=STOPBITS_1
USART3.SwapParam=ADVFEATURE_SWAP_DISABLE
USART3.TXFIFOThreshold=TXFIFO_THRESHOLD_1EIGHTHFULL
USART3.TxPinLevelInvertParam=ADVFEATURE_TXINV_DISABLE
USART3.VirtualMode-Asynchronous=VM_ASYNC
USART3.WordLength=WORDLENGTH_8B
USB_DEVICE.APP_RX_DATA_SIZE-CDC_FS=2048
USB_DEVICE.APP_TX_DATA_SIZE-CDC_FS=2048
USB_DEVICE.CLASS_NAME_FS=CDC
USB_DEVICE.CONFIGURATION_STRING_CDC_FS=CDC Config
USB_DEVICE.INTERFACE_STRING_CDC_FS=CDC Interface
USB_DEVICE.LANGID_STRING-CDC_FS=1033
USB_DEVICE.MANUFACTURER_STRING-CDC_FS=ARIS
USB_DEVICE.PID_CDC_FS=22336
USB_DEVICE.PRODUCT_STRING_CDC_FS=EULER II MAIN BOARD
USB_DEVICE.USBD_DEBUG_LEVEL-CDC_FS=0
USB_DEVICE.USBD_MAX_NUM_CONFIGURATION-CDC_FS=1
USB_DEVICE.USBD_MAX_NUM_INTERFACES-CDC_FS=1
USB_DEVICE.USBD_MAX_STR_DESC_SIZ-CDC_FS=512
USB_DEVICE.USBD_SELF_POWERED-CDC_FS=1
USB_DEVICE.VID-CDC_FS=1155
USB_DEVICE.VirtualMode-CDC_FS=Cdc
USB_DEVICE.VirtualModeFS=Cdc_FS
USB_OTG_FS.Sof_enable=DISABLE
USB_OTG_FS.VirtualMode=Device_Only
USB_OTG_FS.battery_charging_enable=DISABLE
USB_OTG_FS.dma_enable=DISABLE
USB_OTG_FS.low_power_enable=DISABLE
USB_OTG_FS.lpm_enable=DISABLE
USB_OTG_FS.use_dedicated_ep1=DISABLE
USB_OTG_FS.vbus_sensing_enable=DISABLE
VP_FATFS_VS_SDIO.Mode=SDIO
VP_FREERTOS_VS_CMSIS_V2.Mode=CMSIS_V2
VP_SYS_VS_tim1.Mode=TIM1
VP_USB_DEVICE_VS_USB_DEVICE_CDC_FS.Mode=CDC_FS
board=custom

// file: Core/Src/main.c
/* USER CODE BEGIN Header */
/**
 ******************************************************************************
 * @file           : main.c
 * @brief          : Main program body
 ******************************************************************************
 * @attention
 *
 * <h2><center>&copy; Copyright (c) 2020 STMicroelectronics.
 * All rights reserved.</center></h2>
 *
 * This software component is licensed by ST under Ultimate Liberty license
 * SLA0044, the "License"; You may not use this file except in compliance with
 * the License. You may obtain a copy of the License at:
 *                             www.st.com/SLA0044
 *
 ******************************************************************************
 */
/* USER CODE END Header */
#include "main.h"
#include "cmsis_os.h"
#include "fatfs.h"
#include "usb_device.h"

/* USER CODE BEGIN Includes */
#include "tasks/task_controller.h"
#include "tasks/task_sens_read.h"
#include "tasks/task_state_est.h"
#include "tasks/task_motor_control.h"
#include "tasks/task_fsm.h"
#include "tasks/task_gps.h"
#include "tasks/task_battery.h"
#include "tasks/task_sd_card.h"
#include "tasks/task_xbee.h"
#include "Util/logging_util.h"
#include "../aris-euler-state-estimation/Inc/flight_phase_detection.h"
/* USER CODE END Includes */

typedef StaticTask_t osStaticThreadDef_t;

ADC_HandleTypeDef hadc1;
DMA_HandleTypeDef hdma_adc1;

SD_HandleTypeDef hsd1;

SPI_HandleTypeDef hspi1;
SPI_HandleTypeDef hspi2;
SPI_HandleTypeDef hspi3;
SPI_HandleTypeDef hspi4;
DMA_HandleTypeDef hdma_spi1_rx;
DMA_HandleTypeDef hdma_spi2_rx;
DMA_HandleTypeDef hdma_spi3_rx;

TIM_HandleTypeDef htim4;

UART_HandleTypeDef huart4;
UART_HandleTypeDef huart7;
UART_HandleTypeDef huart1;
UART_HandleTypeDef huart2;
UART_HandleTypeDef huart3;
DMA_HandleTypeDef hdma_uart4_rx;
DMA_HandleTypeDef hdma_uart4_tx;
DMA_HandleTypeDef hdma_uart7_tx;
DMA_HandleTypeDef hdma_usart1_rx;
DMA_HandleTypeDef hdma_usart2_rx;
DMA_HandleTypeDef hdma_usart3_rx;

/* Definitions for defaultTask */
osThreadId_t defaultTaskHandle;
const osThreadAttr_t defaultTask_attributes = {
  .name = "defaultTask",
  .priority = (osPriority_t) osPriorityLow,
  .stack_size = 128 * 4
};
/* Definitions for task_state_est */
osThreadId_t task_state_estHandle;
DTCM uint32_t task_state_estBuffer[ 2048 ];
osStaticThreadDef_t task_state_estControlBlock;
const osThreadAttr_t task_state_est_attributes = {
  .name = "task_state_est",
  .stack_mem = &task_state_estBuffer[0],
  .stack_size = sizeof(task_state_estBuffer),
  .cb_mem = &task_state_estControlBlock,
  .cb_size = sizeof(task_state_estControlBlock),
  .priority = (osPriority_t) osPriorityHigh3,
};
/* Definitions for task_controller */
osThreadId_t task_controllerHandle;
DTCM uint32_t task_controllerBuffer[ 2048 ];
osStaticThreadDef_t task_controllerControlBlock;
const osThreadAttr_t task_controller_attributes = {
  .name = "task_controller",
  .stack_mem = &task_controllerBuffer[0],
  .stack_size = sizeof(task_controllerBuffer),
  .cb_mem = &task_controllerControlBlock,
  .cb_size = sizeof(task_controllerControlBlock),
  .priority = (osPriority_t) osPriorityAboveNormal7,
};
/* Definitions for task_sens_read */
osThreadId_t task_sens_readHandle;
DTCM uint32_t task_sens_readBuffer[ 512 ];
osStaticThreadDef_t task_sens_readControlBlock;
const osThreadAttr_t task_sens_read_attributes = {
  .name = "task_sens_read",
  .stack_mem = &task_sens_readBuffer[0],
  .stack_size = sizeof(task_sens_readBuffer),
  .cb_mem = &task_sens_readControlBlock,
  .cb_size = sizeof(task_sens_readControlBlock),
  .priority = (osPriority_t) osPriorityHigh7,
};
/* Definitions for task_sd_card */
osThreadId_t task_sd_cardHandle;
DTCM uint32_t task_sd_cardBuffer[ 1024 ];
osStaticThreadDef_t task_sd_cardControlBlock;
const osThreadAttr_t task_sd_card_attributes = {
  .name = "task_sd_card",
  .stack_mem = &task_sd_cardBuffer[0],
  .stack_size = sizeof(task_sd_cardBuffer),
  .cb_mem = &task_sd_cardControlBlock,
  .cb_size = sizeof(task_sd_cardControlBlock),
  .priority = (osPriority_t) osPriorityHigh1,
};
/* Definitions for task_motor_cont */
osThreadId_t task_motor_contHandle;
uint32_t task_motor_contBuffer[ 512 ];
osStaticThreadDef_t task_motor_contControlBlock;
const osThreadAttr_t task_motor_cont_attributes = {
  .name = "task_motor_cont",
  .stack_mem = &task_motor_contBuffer[0],
  .stack_size = sizeof(task_motor_contBuffer),
  .cb_mem = &task_motor_contControlBlock,
  .cb_size = sizeof(task_motor_contControlBlock),
  .priority = (osPriority_t) osPriorityAboveNormal6,
};
/* Definitions for task_fsm */
osThreadId_t task_fsmHandle;
DTCM uint32_t task_fsmBuffer[ 512 ];
osStaticThreadDef_t task_fsmControlBlock;
const osThreadAttr_t task_fsm_attributes = {
  .name = "task_fsm",
  .stack_mem = &task_fsmBuffer[0],
  .stack_size = sizeof(task_fsmBuffer),
  .cb_mem = &task_fsmControlBlock,
  .cb_size = sizeof(task_fsmControlBlock),
  .priority = (osPriority_t) osPriorityHigh5,
};
/* Definitions for task_gps */
osThreadId_t task_gpsHandle;
uint32_t task_gpsBuffer[ 512 ];
osStaticThreadDef_t task_gpsControlBlock;
const osThreadAttr_t task_gps_attributes = {
  .name = "task_gps",
  .stack_mem = &task_gpsBuffer[0],
  .stack_size = sizeof(task_gpsBuffer),
  .cb_mem = &task_gpsControlBlock,
  .cb_size = sizeof(task_gpsControlBlock),
  .priority = (osPriority_t) osPriorityHigh6,
};
/* Definitions for task_battery */
osThreadId_t task_batteryHandle;
DTCM uint32_t task_batteryBuffer[ 512 ];
osStaticThreadDef_t task_batteryControlBlock;
const osThreadAttr_t task_battery_attributes = {
  .name = "task_battery",
  .stack_mem = &task_batteryBuffer[0],
  .stack_size = sizeof(task_batteryBuffer),
  .cb_mem = &task_batteryControlBlock,
  .cb_size = sizeof(task_batteryControlBlock),
  .priority = (osPriority_t) osPriorityHigh,
};
/* Definitions for task_xbee */
osThreadId_t task_xbeeHandle;
DTCM uint32_t task_xbeeBuffer[ 512 ];
osStaticThreadDef_t task_xbeeControlBlock;
const osThreadAttr_t task_xbee_attributes = {
  .name = "task_xbee",
  .stack_mem = &task_xbeeBuffer[0],
  .stack_size = sizeof(task_xbeeBuffer),
  .cb_mem = &task_xbeeControlBlock,
  .cb_size = sizeof(task_xbeeControlBlock),
  .priority = (osPriority_t) osPriorityHigh4,
};
/* Definitions for task_peripherals */
osThreadId_t task_peripheralsHandle;
uint32_t task_peripheralsBuffer[ 128 ];
osStaticThreadDef_t task_peripheralsControlBlock;
const osThreadAttr_t task_peripherals_attributes = {
  .name = "task_peripherals",
  .stack_mem = &task_peripheralsBuffer[0],
  .stack_size = sizeof(task_peripheralsBuffer),
  .cb_mem = &task_peripheralsControlBlock,
  .cb_size = sizeof(task_peripheralsControlBlock),
  .priority = (osPriority_t) osPriorityHigh2,
};
/* USER CODE BEGIN PV */

/** SENSOR BOARD VARIABLES **/

sb_data_t sb1_global = { 0 };
sb_data_t sb2_global = { 0 };
sb_data_t sb3_global = { 0 };

/** CONTROL VARIABLES **/

state_est_data_t state_est_data_global = {0};
int32_t controller_output_global = 0;
env_t global_env = {0};
flight_phase_detection_t global_flight_phase_detection = {0};

/** MOTOR CONTROLLER VARIABLES **/
int32_t global_airbrake_ext_meas = 0;

/** TELEMETRY COMMAND **/
command_e global_telemetry_command;
uint8_t sd_card_logging_status = 0;

/** MUTEXES **/

/* Sensor Board */
osMutexId_t sb1_mutex_only;
custom_mutex_t sb1_mutex;
osMutexId_t sb2_mutex_only;
custom_mutex_t sb2_mutex;
osMutexId_t sb3_mutex_only;
custom_mutex_t sb3_mutex;

/* Control */
osMutexId_t environment_mutex_only;
custom_mutex_t env_mutex;
osMutexId_t state_est_mutex_only;
custom_mutex_t state_est_mutex;
osMutexId_t controller_mutex_only;
custom_mutex_t controller_mutex;

/* Motor Controller */
osMutexId_t airbrake_ext_mutex_only;
custom_mutex_t airbrake_ext_mutex;

/* FSM */
osMutexId_t fsm_mutex_only;
custom_mutex_t fsm_mutex;

/* GPS */
gps_data_t globalGPS;

osMutexId_t gps_mutex_only;
custom_mutex_t gps_mutex;

/* Battery */
osMutexId_t battery_mutex_only;
telemetry_battery_data_t global_battery_data;
custom_mutex_t battery_mutex;

/* Peripherals */
int8_t buzzer_state;
int8_t camera_state;

/* Telemetry Command */
osMutexId_t command_mutex_only;
custom_mutex_t command_mutex;

/* USB debugging */
osMutexId_t usb_data_mutex_only;
custom_mutex_t usb_data_mutex;
char usb_data_buffer[256] = {0};

/** Logging Queue **/
osMessageQueueId_t sd_queue;
osMessageQueueId_t flash_queue;

/* USER CODE END PV */

void SystemClock_Config(void);
static void MX_GPIO_Init(void);
static void MX_DMA_Init(void);
static void MX_ADC1_Init(void);
static void MX_SPI1_Init(void);
static void MX_SPI2_Init(void);
static void MX_SPI3_Init(void);
static void MX_UART4_Init(void);
static void MX_UART7_Init(void);
static void MX_USART1_UART_Init(void);
static void MX_USART2_UART_Init(void);
static void MX_USART3_UART_Init(void);
static void MX_SPI4_Init(void);
static void MX_TIM4_Init(void);
void StartDefaultTask(void *argument);
extern void vTaskStateEst(void *argument);
extern void vTaskController(void *argument);
extern void vTaskSensRead(void *argument);
extern void vTaskSdCard(void *argument);
extern void vTaskMotorCont(void *argument);
extern void vTaskFsm(void *argument);
extern void vTaskGps(void *argument);
extern void vTaskBattery(void *argument);
extern void vTaskXbee(void *argument);
extern void vTaskPeripherals(void *argument);

int main(void)
{

  /* Enable I-Cache---------------------------------------------------------*/
  SCB_EnableICache();

  /* MCU Configuration--------------------------------------------------------*/

  /* Reset of all peripherals, Initializes the Flash interface and the Systick. */
  HAL_Init();

  /* Configure the system clock */
  SystemClock_Config();

  /* USER CODE BEGIN SysInit */
  init_env(&global_env);
  reset_flight_phase_detection(&global_flight_phase_detection);
  /* USER CODE END SysInit */

  /* Initialize all configured peripherals */
  MX_GPIO_Init();
  MX_DMA_Init();
  MX_ADC1_Init();
  MX_SDMMC1_SD_Init();
  MX_SPI1_Init();
  MX_SPI2_Init();
  MX_SPI3_Init();
  MX_UART4_Init();
  MX_UART7_Init();
  MX_USART1_UART_Init();
  MX_USART2_UART_Init();
  MX_USART3_UART_Init();
  MX_FATFS_Init();
  MX_SPI4_Init();
  MX_TIM4_Init();
  /* USER CODE BEGIN 2 */
//  MX_USB_DEVICE_Init();
#if (configUSE_TRACE_FACILITY == 1)
  vTraceEnable(TRC_INIT);
#endif
  /* USER CODE END 2 */

  /* Init scheduler */
  osKernelInitialize();

  /* USER CODE BEGIN RTOS_MUTEX */
  /* Sensor Board 1 Mutex */
  const osMutexAttr_t sb1_mutex_attr = {
      "sb1_mutex_only",    // human readable mutex name
      osMutexPrioInherit,  // attr_bits
      NULL,                // memory for control block
      0U                   // size for control block
  };

  sb1_mutex_only = osMutexNew(&sb1_mutex_attr);

  /* Sensor Board 2 Mutex */
  const osMutexAttr_t sb2_mutex_attr = {
      "sb2_mutex_only",    // human readable mutex name
      osMutexPrioInherit,  // attr_bits
      NULL,                // memory for control block
      0U                   // size for control block
  };

  sb2_mutex_only = osMutexNew(&sb2_mutex_attr);

  /* Sensor Board 3 Mutex */
  const osMutexAttr_t sb3_mutex_attr = {
      "sb3_mutex_only",    // human readable mutex name
      osMutexPrioInherit,  // attr_bits
      NULL,                // memory for control block
      0U                   // size for control block
  };

  sb3_mutex_only = osMutexNew(&sb3_mutex_attr);

  /* State Estimation Output Mutex */
  const osMutexAttr_t state_est_mutex_attr = {
      "state_est_mutex_only",  // human readable mutex name
      osMutexPrioInherit,      // attr_bits
      NULL,                    // memory for control block
      0U                       // size for control block
  };

  state_est_mutex_only = osMutexNew(&state_est_mutex_attr);

  /* Controller Output Mutex */
  const osMutexAttr_t controller_mutex_attr = {
      "controller_mutex_only",  // human readable mutex name
      osMutexPrioInherit,       // attr_bits
      NULL,                     // memory for control block
      0U                        // size for control block
  };

  controller_mutex_only = osMutexNew(&controller_mutex_attr);

  /* FSM Output Mutex */
  const osMutexAttr_t fsm_mutex_attr = {
      "fsm_mutex_only",    // human readable mutex name
      osMutexPrioInherit,  // attr_bits
      NULL,                // memory for control block
      0U                   // size for control block
  };

  fsm_mutex_only = osMutexNew(&fsm_mutex_attr);

  /* Environment Mutex */
  const osMutexAttr_t environment_mutex_attr = {
      "environment_mutex_only",  // human readable mutex name
      osMutexPrioInherit,        // attr_bits
      NULL,                      // memory for control block
      0U                         // size for control block
  };

  environment_mutex_only = osMutexNew(&environment_mutex_attr);

  /* USB Data Mutex */
  const osMutexAttr_t usb_data_mutex_attr = {
      "usb_data_mutex_only",  // human readable mutex name
      osMutexPrioInherit,     // attr_bits
      NULL,                   // memory for control block
      0U                      // size for control block
  };

  usb_data_mutex_only = osMutexNew(&usb_data_mutex_attr);

  /* Command Mutex */
  const osMutexAttr_t command_mutex_attr = {
      "command_mutex_only",  // human readable mutex name
      osMutexPrioInherit,    // attr_bits
      NULL,                  // memory for control block
      0U                     // size for control block
  };

  command_mutex_only = osMutexNew(&command_mutex_attr);

  /* GPS Mutex */
  const osMutexAttr_t gps_mutex_attr = {
      "gps_mutex_only",    // human readable mutex name
      osMutexPrioInherit,  // attr_bits
      NULL,                // memory for control block
      0U                   // size for control block
  };

  gps_mutex_only = osMutexNew(&gps_mutex_attr);

  /* Battery Mutex */
  const osMutexAttr_t battery_mutex_attr = {
      "battery_mutex_only",  // human readable mutex name
      osMutexPrioInherit,    // attr_bits
      NULL,                  // memory for control block
      0U                     // size for control block
  };

  battery_mutex_only = osMutexNew(&battery_mutex_attr);

  /* Motor Mutex */
  const osMutexAttr_t airbrake_ext_mutex_attr = {
      "airbrake_ext_mutex_only",  // human readable mutex name
      osMutexPrioInherit,  // attr_bits
      NULL,                // memory for control block
      0U                   // size for control block
  };

  airbrake_ext_mutex_only = osMutexNew(&airbrake_ext_mutex_attr);

  /** Initialise Mutexes **/

  sb1_mutex.mutex = sb1_mutex_only;
  sb2_mutex.mutex = sb2_mutex_only;
  sb3_mutex.mutex = sb3_mutex_only;
  env_mutex.mutex = environment_mutex_only;
  fsm_mutex.mutex = fsm_mutex_only;
  controller_mutex.mutex = controller_mutex_only;
  state_est_mutex.mutex = state_est_mutex_only;
  usb_data_mutex.mutex = usb_data_mutex_only;
  command_mutex.mutex = command_mutex_only;
  gps_mutex.mutex = gps_mutex_only;
  battery_mutex.mutex = battery_mutex_only;
  airbrake_ext_mutex.mutex = airbrake_ext_mutex_only;

  global_flight_phase_detection.flight_phase = IDLE;
  global_flight_phase_detection.mach_regime = SUBSONIC;
  global_telemetry_command = IDLE_COMMAND;

#ifdef DEBUG
  const osMutexAttr_t print_mutex_attr = {
      "print_mutex",       // human readable mutex name
      osMutexPrioInherit,  // attr_bits
      NULL,                // memory for control block
      0U                   // size for control block
  };

  print_mutex = osMutexNew(&print_mutex_attr);
#endif
  /* USER CODE END RTOS_MUTEX */

  /* USER CODE BEGIN RTOS_QUEUES */
  sd_queue = osMessageQueueNew(SD_QUEUE_SIZE, sizeof(log_elem_t), NULL);
#if (configUSE_TRACE_FACILITY == 1)
  vTraceSetQueueName(sd_queue, "SD Queue");
#endif
  /* USER CODE END RTOS_QUEUES */

  /* Create the thread(s) */
  /* creation of defaultTask */
  defaultTaskHandle = osThreadNew(StartDefaultTask, NULL, &defaultTask_attributes);

  /* creation of task_state_est */
  task_state_estHandle = osThreadNew(vTaskStateEst, NULL, &task_state_est_attributes);

  /* creation of task_controller */
  task_controllerHandle = osThreadNew(vTaskController, NULL, &task_controller_attributes);

  /* creation of task_sens_read */
  task_sens_readHandle = osThreadNew(vTaskSensRead, NULL, &task_sens_read_attributes);

  /* creation of task_sd_card */
  task_sd_cardHandle = osThreadNew(vTaskSdCard, NULL, &task_sd_card_attributes);

  /* creation of task_motor_cont */
  task_motor_contHandle = osThreadNew(vTaskMotorCont, NULL, &task_motor_cont_attributes);

  /* creation of task_fsm */
  task_fsmHandle = osThreadNew(vTaskFsm, NULL, &task_fsm_attributes);

  /* creation of task_gps */
  task_gpsHandle = osThreadNew(vTaskGps, NULL, &task_gps_attributes);

  /* creation of task_battery */
  task_batteryHandle = osThreadNew(vTaskBattery, NULL, &task_battery_attributes);

  /* creation of task_xbee */
  task_xbeeHandle = osThreadNew(vTaskXbee, NULL, &task_xbee_attributes);

  /* creation of task_peripherals */
  task_peripheralsHandle = osThreadNew(vTaskPeripherals, NULL, &task_peripherals_attributes);

  /* Start scheduler */
  osKernelStart();

  /* We should never get here as control is now taken by the scheduler */
  /* Infinite loop */
  while (1) {

  }
}

void SystemClock_Config(void)
{
  RCC_OscInitTypeDef RCC_OscInitStruct = {0};
  RCC_ClkInitTypeDef RCC_ClkInitStruct = {0};
  RCC_PeriphCLKInitTypeDef PeriphClkInitStruct = {0};

  /** Supply configuration update enable
  */
  HAL_PWREx_ConfigSupply(PWR_LDO_SUPPLY);
  /** Configure the main internal regulator output voltage
  */
  __HAL_PWR_VOLTAGESCALING_CONFIG(PWR_REGULATOR_VOLTAGE_SCALE0);

  while(!__HAL_PWR_GET_FLAG(PWR_FLAG_VOSRDY)) {}
  /** Macro to configure the PLL clock source
  */
  __HAL_RCC_PLL_PLLSOURCE_CONFIG(RCC_PLLSOURCE_HSE);
  /** Initializes the RCC Oscillators according to the specified parameters
  * in the RCC_OscInitTypeDef structure.
  */
  RCC_OscInitStruct.OscillatorType = RCC_OSCILLATORTYPE_HSI48|RCC_OSCILLATORTYPE_HSE;
  RCC_OscInitStruct.HSEState = RCC_HSE_ON;
  RCC_OscInitStruct.HSI48State = RCC_HSI48_ON;
  RCC_OscInitStruct.PLL.PLLState = RCC_PLL_ON;
  RCC_OscInitStruct.PLL.PLLSource = RCC_PLLSOURCE_HSE;
  RCC_OscInitStruct.PLL.PLLM = 1;
  RCC_OscInitStruct.PLL.PLLN = 120;
  RCC_OscInitStruct.PLL.PLLP = 2;
  RCC_OscInitStruct.PLL.PLLQ = 8;
  RCC_OscInitStruct.PLL.PLLR = 2;
  RCC_OscInitStruct.PLL.PLLRGE = RCC_PLL1VCIRANGE_3;
  RCC_OscInitStruct.PLL.PLLVCOSEL = RCC_PLL1VCOWIDE;
  RCC_OscInitStruct.PLL.PLLFRACN = 0;
  if (HAL_RCC_OscConfig(&RCC_OscInitStruct) != HAL_OK)
  {
    Error_Handler();
  }
  /** Initializes the CPU, AHB and APB buses clocks
  */
  RCC_ClkInitStruct.ClockType = RCC_CLOCKTYPE_HCLK|RCC_CLOCKTYPE_SYSCLK
                              |RCC_CLOCKTYPE_PCLK1|RCC_CLOCKTYPE_PCLK2
                              |RCC_CLOCKTYPE_D3PCLK1|RCC_CLOCKTYPE_D1PCLK1;
  RCC_ClkInitStruct.SYSCLKSource = RCC_SYSCLKSOURCE_PLLCLK;
  RCC_ClkInitStruct.SYSCLKDivider = RCC_SYSCLK_DIV1;
  RCC_ClkInitStruct.AHBCLKDivider = RCC_HCLK_DIV2;
  RCC_ClkInitStruct.APB3CLKDivider = RCC_APB3_DIV2;
  RCC_ClkInitStruct.APB1CLKDivider = RCC_APB1_DIV2;
  RCC_ClkInitStruct.APB2CLKDivider = RCC_APB2_DIV2;
  RCC_ClkInitStruct.APB4CLKDivider = RCC_APB4_DIV2;

  if (HAL_RCC_ClockConfig(&RCC_ClkInitStruct, FLASH_LATENCY_4) != HAL_OK)
  {
    Error_Handler();
  }
  PeriphClkInitStruct.PeriphClockSelection = RCC_PERIPHCLK_USART3|RCC_PERIPHCLK_USART2
                              |RCC_PERIPHCLK_UART4|RCC_PERIPHCLK_UART7
                              |RCC_PERIPHCLK_USART1|RCC_PERIPHCLK_SPI4
                              |RCC_PERIPHCLK_SPI3|RCC_PERIPHCLK_SPI1
                              |RCC_PERIPHCLK_SPI2|RCC_PERIPHCLK_SDMMC
                              |RCC_PERIPHCLK_ADC|RCC_PERIPHCLK_USB;
  PeriphClkInitStruct.PLL2.PLL2M = 1;
  PeriphClkInitStruct.PLL2.PLL2N = 18;
  PeriphClkInitStruct.PLL2.PLL2P = 1;
  PeriphClkInitStruct.PLL2.PLL2Q = 2;
  PeriphClkInitStruct.PLL2.PLL2R = 2;
  PeriphClkInitStruct.PLL2.PLL2RGE = RCC_PLL2VCIRANGE_3;
  PeriphClkInitStruct.PLL2.PLL2VCOSEL = RCC_PLL2VCOMEDIUM;
  PeriphClkInitStruct.PLL2.PLL2FRACN = 6144;
  PeriphClkInitStruct.SdmmcClockSelection = RCC_SDMMCCLKSOURCE_PLL;
  PeriphClkInitStruct.Spi123ClockSelection = RCC_SPI123CLKSOURCE_PLL;
  PeriphClkInitStruct.Spi45ClockSelection = RCC_SPI45CLKSOURCE_D2PCLK1;
  PeriphClkInitStruct.Usart234578ClockSelection = RCC_USART234578CLKSOURCE_D2PCLK1;
  PeriphClkInitStruct.Usart16ClockSelection = RCC_USART16CLKSOURCE_D2PCLK2;
  PeriphClkInitStruct.UsbClockSelection = RCC_USBCLKSOURCE_HSI48;
  PeriphClkInitStruct.AdcClockSelection = RCC_ADCCLKSOURCE_PLL2;
  if (HAL_RCCEx_PeriphCLKConfig(&PeriphClkInitStruct) != HAL_OK)
  {
    Error_Handler();
  }
  /** Enable USB Voltage detector
  */
  HAL_PWREx_EnableUSBVoltageDetector();
}

static void MX_ADC1_Init(void)
{

  ADC_MultiModeTypeDef multimode = {0};
  ADC_ChannelConfTypeDef sConfig = {0};

  /** Common config
  */
  hadc1.Instance = ADC1;
  hadc1.Init.ClockPrescaler = ADC_CLOCK_ASYNC_DIV8;
  hadc1.Init.Resolution = ADC_RESOLUTION_16B;
  hadc1.Init.ScanConvMode = ADC_SCAN_ENABLE;
  hadc1.Init.EOCSelection = ADC_EOC_SINGLE_CONV;
  hadc1.Init.LowPowerAutoWait = DISABLE;
  hadc1.Init.ContinuousConvMode = ENABLE;
  hadc1.Init.NbrOfConversion = 4;
  hadc1.Init.DiscontinuousConvMode = DISABLE;
  hadc1.Init.ExternalTrigConv = ADC_SOFTWARE_START;
  hadc1.Init.ExternalTrigConvEdge = ADC_EXTERNALTRIGCONVEDGE_NONE;
  hadc1.Init.ConversionDataManagement = ADC_CONVERSIONDATA_DMA_CIRCULAR;
  hadc1.Init.Overrun = ADC_OVR_DATA_PRESERVED;
  hadc1.Init.LeftBitShift = ADC_LEFTBITSHIFT_NONE;
  hadc1.Init.OversamplingMode = DISABLE;
  if (HAL_ADC_Init(&hadc1) != HAL_OK)
  {
    Error_Handler();
  }
  /** Configure the ADC multi-mode
  */
  multimode.Mode = ADC_MODE_INDEPENDENT;
  if (HAL_ADCEx_MultiModeConfigChannel(&hadc1, &multimode) != HAL_OK)
  {
    Error_Handler();
  }
  /** Configure Regular Channel
  */
  sConfig.Channel = ADC_CHANNEL_8;
  sConfig.Rank = ADC_REGULAR_RANK_1;
  sConfig.SamplingTime = ADC_SAMPLETIME_387CYCLES_5;
  sConfig.SingleDiff = ADC_SINGLE_ENDED;
  sConfig.OffsetNumber = ADC_OFFSET_NONE;
  sConfig.Offset = 0;
  sConfig.OffsetSignedSaturation = DISABLE;
  if (HAL_ADC_ConfigChannel(&hadc1, &sConfig) != HAL_OK)
  {
    Error_Handler();
  }
  /** Configure Regular Channel
  */
  sConfig.Channel = ADC_CHANNEL_9;
  sConfig.Rank = ADC_REGULAR_RANK_2;
  if (HAL_ADC_ConfigChannel(&hadc1, &sConfig) != HAL_OK)
  {
    Error_Handler();
  }
  /** Configure Regular Channel
  */
  sConfig.Channel = ADC_CHANNEL_10;
  sConfig.Rank = ADC_REGULAR_RANK_3;
  if (HAL_ADC_ConfigChannel(&hadc1, &sConfig) != HAL_OK)
  {
    Error_Handler();
  }
  /** Configure Regular Channel
  */
  sConfig.Channel = ADC_CHANNEL_11;
  sConfig.Rank = ADC_REGULAR_RANK_4;
  if (HAL_ADC_ConfigChannel(&hadc1, &sConfig) != HAL_OK)
  {
    Error_Handler();
  }

}

void MX_SDMMC1_SD_Init(void)
{

  hsd1.Instance = SDMMC1;
  hsd1.Init.ClockEdge = SDMMC_CLOCK_EDGE_RISING;
  hsd1.Init.ClockPowerSave = SDMMC_CLOCK_POWER_SAVE_DISABLE;
  hsd1.Init.BusWide = SDMMC_BUS_WIDE_4B;
  hsd1.Init.HardwareFlowControl = SDMMC_HARDWARE_FLOW_CONTROL_DISABLE;
  hsd1.Init.ClockDiv = 0;
  hsd1.Init.TranceiverPresent = SDMMC_TRANSCEIVER_NOT_PRESENT;

}

static void MX_SPI1_Init(void)
{

  /* SPI1 parameter configuration*/
  hspi1.Instance = SPI1;
  hspi1.Init.Mode = SPI_MODE_SLAVE;
  hspi1.Init.Direction = SPI_DIRECTION_2LINES_RXONLY;
  hspi1.Init.DataSize = SPI_DATASIZE_8BIT;
  hspi1.Init.CLKPolarity = SPI_POLARITY_LOW;
  hspi1.Init.CLKPhase = SPI_PHASE_1EDGE;
  hspi1.Init.NSS = SPI_NSS_SOFT;
  hspi1.Init.FirstBit = SPI_FIRSTBIT_MSB;
  hspi1.Init.TIMode = SPI_TIMODE_DISABLE;
  hspi1.Init.CRCCalculation = SPI_CRCCALCULATION_DISABLE;
  hspi1.Init.CRCPolynomial = 0x0;
  hspi1.Init.NSSPMode = SPI_NSS_PULSE_DISABLE;
  hspi1.Init.NSSPolarity = SPI_NSS_POLARITY_LOW;
  hspi1.Init.FifoThreshold = SPI_FIFO_THRESHOLD_01DATA;
  hspi1.Init.TxCRCInitializationPattern = SPI_CRC_INITIALIZATION_ALL_ZERO_PATTERN;
  hspi1.Init.RxCRCInitializationPattern = SPI_CRC_INITIALIZATION_ALL_ZERO_PATTERN;
  hspi1.Init.MasterSSIdleness = SPI_MASTER_SS_IDLENESS_00CYCLE;
  hspi1.Init.MasterInterDataIdleness = SPI_MASTER_INTERDATA_IDLENESS_00CYCLE;
  hspi1.Init.MasterReceiverAutoSusp = SPI_MASTER_RX_AUTOSUSP_DISABLE;
  hspi1.Init.MasterKeepIOState = SPI_MASTER_KEEP_IO_STATE_DISABLE;
  hspi1.Init.IOSwap = SPI_IO_SWAP_DISABLE;
  if (HAL_SPI_Init(&hspi1) != HAL_OK)
  {
    Error_Handler();
  }

}

static void MX_SPI2_Init(void)
{

  /* SPI2 parameter configuration*/
  hspi2.Instance = SPI2;
  hspi2.Init.Mode = SPI_MODE_SLAVE;
  hspi2.Init.Direction = SPI_DIRECTION_2LINES_RXONLY;
  hspi2.Init.DataSize = SPI_DATASIZE_8BIT;
  hspi2.Init.CLKPolarity = SPI_POLARITY_LOW;
  hspi2.Init.CLKPhase = SPI_PHASE_1EDGE;
  hspi2.Init.NSS = SPI_NSS_SOFT;
  hspi2.Init.FirstBit = SPI_FIRSTBIT_MSB;
  hspi2.Init.TIMode = SPI_TIMODE_DISABLE;
  hspi2.Init.CRCCalculation = SPI_CRCCALCULATION_DISABLE;
  hspi2.Init.CRCPolynomial = 0x0;
  hspi2.Init.NSSPMode = SPI_NSS_PULSE_DISABLE;
  hspi2.Init.NSSPolarity = SPI_NSS_POLARITY_LOW;
  hspi2.Init.FifoThreshold = SPI_FIFO_THRESHOLD_01DATA;
  hspi2.Init.TxCRCInitializationPattern = SPI_CRC_INITIALIZATION_ALL_ZERO_PATTERN;
  hspi2.Init.RxCRCInitializationPattern = SPI_CRC_INITIALIZATION_ALL_ZERO_PATTERN;
  hspi2.Init.MasterSSIdleness = SPI_MASTER_SS_IDLENESS_00CYCLE;
  hspi2.Init.MasterInterDataIdleness = SPI_MASTER_INTERDATA_IDLENESS_00CYCLE;
  hspi2.Init.MasterReceiverAutoSusp = SPI_MASTER_RX_AUTOSUSP_DISABLE;
  hspi2.Init.MasterKeepIOState = SPI_MASTER_KEEP_IO_STATE_DISABLE;
  hspi2.Init.IOSwap = SPI_IO_SWAP_DISABLE;
  if (HAL_SPI_Init(&hspi2) != HAL_OK)
  {
    Error_Handler();
  }

}

static void MX_SPI3_Init(void)
{

  /* SPI3 parameter configuration*/
  hspi3.Instance = SPI3;
  hspi3.Init.Mode = SPI_MODE_SLAVE;
  hspi3.Init.Direction = SPI_DIRECTION_2LINES_RXONLY;
  hspi3.Init.DataSize = SPI_DATASIZE_8BIT;
  hspi3.Init.CLKPolarity = SPI_POLARITY_LOW;
  hspi3.Init.CLKPhase = SPI_PHASE_1EDGE;
  hspi3.Init.NSS = SPI_NSS_SOFT;
  hspi3.Init.FirstBit = SPI_FIRSTBIT_MSB;
  hspi3.Init.TIMode = SPI_TIMODE_DISABLE;
  hspi3.Init.CRCCalculation = SPI_CRCCALCULATION_DISABLE;
  hspi3.Init.CRCPolynomial = 0x0;
  hspi3.Init.NSSPMode = SPI_NSS_PULSE_DISABLE;
  hspi3.Init.NSSPolarity = SPI_NSS_POLARITY_LOW;
  hspi3.Init.FifoThreshold = SPI_FIFO_THRESHOLD_01DATA;
  hspi3.Init.TxCRCInitializationPattern = SPI_CRC_INITIALIZATION_ALL_ZERO_PATTERN;
  hspi3.Init.RxCRCInitializationPattern = SPI_CRC_INITIALIZATION_ALL_ZERO_PATTERN;
  hspi3.Init.MasterSSIdleness = SPI_MASTER_SS_IDLENESS_00CYCLE;
  hspi3.Init.MasterInterDataIdleness = SPI_MASTER_INTERDATA_IDLENESS_00CYCLE;
  hspi3.Init.MasterReceiverAutoSusp = SPI_MASTER_RX_AUTOSUSP_DISABLE;
  hspi3.Init.MasterKeepIOState = SPI_MASTER_KEEP_IO_STATE_DISABLE;
  hspi3.Init.IOSwap = SPI_IO_SWAP_DISABLE;
  if (HAL_SPI_Init(&hspi3) != HAL_OK)
  {
    Error_Handler();
  }

}

static void MX_SPI4_Init(void)
{

  /* SPI4 parameter configuration*/
  hspi4.Instance = SPI4;
  hspi4.Init.Mode = SPI_MODE_MASTER;
  hspi4.Init.Direction = SPI_DIRECTION_2LINES;
  hspi4.Init.DataSize = SPI_DATASIZE_8BIT;
  hspi4.Init.CLKPolarity = SPI_POLARITY_LOW;
  hspi4.Init.CLKPhase = SPI_PHASE_1EDGE;
  hspi4.Init.NSS = SPI_NSS_SOFT;
  hspi4.Init.BaudRatePrescaler = SPI_BAUDRATEPRESCALER_64;
  hspi4.Init.FirstBit = SPI_FIRSTBIT_MSB;
  hspi4.Init.TIMode = SPI_TIMODE_DISABLE;
  hspi4.Init.CRCCalculation = SPI_CRCCALCULATION_DISABLE;
  hspi4.Init.CRCPolynomial = 0x0;
  hspi4.Init.NSSPMode = SPI_NSS_PULSE_ENABLE;
  hspi4.Init.NSSPolarity = SPI_NSS_POLARITY_LOW;
  hspi4.Init.FifoThreshold = SPI_FIFO_THRESHOLD_01DATA;
  hspi4.Init.TxCRCInitializationPattern = SPI_CRC_INITIALIZATION_ALL_ZERO_PATTERN;
  hspi4.Init.RxCRCInitializationPattern = SPI_CRC_INITIALIZATION_ALL_ZERO_PATTERN;
  hspi4.Init.MasterSSIdleness = SPI_MASTER_SS_IDLENESS_00CYCLE;
  hspi4.Init.MasterInterDataIdleness = SPI_MASTER_INTERDATA_IDLENESS_00CYCLE;
  hspi4.Init.MasterReceiverAutoSusp = SPI_MASTER_RX_AUTOSUSP_DISABLE;
  hspi4.Init.MasterKeepIOState = SPI_MASTER_KEEP_IO_STATE_DISABLE;
  hspi4.Init.IOSwap = SPI_IO_SWAP_DISABLE;
  if (HAL_SPI_Init(&hspi4) != HAL_OK)
  {
    Error_Handler();
  }

}

static void MX_TIM4_Init(void)
{

  TIM_MasterConfigTypeDef sMasterConfig = {0};
  TIM_OC_InitTypeDef sConfigOC = {0};

  htim4.Instance = TIM4;
  htim4.Init.Prescaler = 240;
  htim4.Init.CounterMode = TIM_COUNTERMODE_UP;
  htim4.Init.Period = 250;
  htim4.Init.ClockDivision = TIM_CLOCKDIVISION_DIV1;
  htim4.Init.AutoReloadPreload = TIM_AUTORELOAD_PRELOAD_DISABLE;
  if (HAL_TIM_PWM_Init(&htim4) != HAL_OK)
  {
    Error_Handler();
  }
  sMasterConfig.MasterOutputTrigger = TIM_TRGO_RESET;
  sMasterConfig.MasterSlaveMode = TIM_MASTERSLAVEMODE_DISABLE;
  if (HAL_TIMEx_MasterConfigSynchronization(&htim4, &sMasterConfig) != HAL_OK)
  {
    Error_Handler();
  }
  sConfigOC.OCMode = TIM_OCMODE_PWM1;
  sConfigOC.Pulse = 125;
  sConfigOC.OCPolarity = TIM_OCPOLARITY_HIGH;
  sConfigOC.OCFastMode = TIM_OCFAST_DISABLE;
  if (HAL_TIM_PWM_ConfigChannel(&htim4, &sConfigOC, TIM_CHANNEL_2) != HAL_OK)
  {
    Error_Handler();
  }
  HAL_TIM_MspPostInit(&htim4);

}

static void MX_UART4_Init(void)
{

  huart4.Instance = UART4;
  huart4.Init.BaudRate = 115200;
  huart4.Init.WordLength = UART_WORDLENGTH_8B;
  huart4.Init.StopBits = UART_STOPBITS_1;
  huart4.Init.Parity = UART_PARITY_NONE;
  huart4.Init.Mode = UART_MODE_TX_RX;
  huart4.Init.HwFlowCtl = UART_HWCONTROL_NONE;
  huart4.Init.OverSampling = UART_OVERSAMPLING_16;
  huart4.Init.OneBitSampling = UART_ONE_BIT_SAMPLE_DISABLE;
  huart4.Init.ClockPrescaler = UART_PRESCALER_DIV1;
  huart4.AdvancedInit.AdvFeatureInit = UART_ADVFEATURE_NO_INIT;
  if (HAL_UART_Init(&huart4) != HAL_OK)
  {
    Error_Handler();
  }
  if (HAL_UARTEx_SetTxFifoThreshold(&huart4, UART_TXFIFO_THRESHOLD_1_8) != HAL_OK)
  {
    Error_Handler();
  }
  if (HAL_UARTEx_SetRxFifoThreshold(&huart4, UART_RXFIFO_THRESHOLD_1_8) != HAL_OK)
  {
    Error_Handler();
  }
  if (HAL_UARTEx_DisableFifoMode(&huart4) != HAL_OK)
  {
    Error_Handler();
  }

}

static void MX_UART7_Init(void)
{

  huart7.Instance = UART7;
  huart7.Init.BaudRate = 115200;
  huart7.Init.WordLength = UART_WORDLENGTH_8B;
  huart7.Init.StopBits = UART_STOPBITS_1;
  huart7.Init.Parity = UART_PARITY_NONE;
  huart7.Init.Mode = UART_MODE_TX_RX;
  huart7.Init.HwFlowCtl = UART_HWCONTROL_NONE;
  huart7.Init.OverSampling = UART_OVERSAMPLING_16;
  huart7.Init.OneBitSampling = UART_ONE_BIT_SAMPLE_DISABLE;
  huart7.Init.ClockPrescaler = UART_PRESCALER_DIV1;
  huart7.AdvancedInit.AdvFeatureInit = UART_ADVFEATURE_SWAP_INIT;
  huart7.AdvancedInit.Swap = UART_ADVFEATURE_SWAP_ENABLE;
  if (HAL_UART_Init(&huart7) != HAL_OK)
  {
    Error_Handler();
  }
  if (HAL_UARTEx_SetTxFifoThreshold(&huart7, UART_TXFIFO_THRESHOLD_1_8) != HAL_OK)
  {
    Error_Handler();
  }
  if (HAL_UARTEx_SetRxFifoThreshold(&huart7, UART_RXFIFO_THRESHOLD_1_8) != HAL_OK)
  {
    Error_Handler();
  }
  if (HAL_UARTEx_DisableFifoMode(&huart7) != HAL_OK)
  {
    Error_Handler();
  }

}

static void MX_USART1_UART_Init(void)
{

  huart1.Instance = USART1;
  huart1.Init.BaudRate = 115200;
  huart1.Init.WordLength = UART_WORDLENGTH_8B;
  huart1.Init.StopBits = UART_STOPBITS_1;
  huart1.Init.Parity = UART_PARITY_NONE;
  huart1.Init.Mode = UART_MODE_TX_RX;
  huart1.Init.HwFlowCtl = UART_HWCONTROL_NONE;
  huart1.Init.OverSampling = UART_OVERSAMPLING_16;
  huart1.Init.OneBitSampling = UART_ONE_BIT_SAMPLE_DISABLE;
  huart1.Init.ClockPrescaler = UART_PRESCALER_DIV1;
  huart1.AdvancedInit.AdvFeatureInit = UART_ADVFEATURE_NO_INIT;
  if (HAL_UART_Init(&huart1) != HAL_OK)
  {
    Error_Handler();
  }
  if (HAL_UARTEx_SetTxFifoThreshold(&huart1, UART_TXFIFO_THRESHOLD_1_8) != HAL_OK)
  {
    Error_Handler();
  }
  if (HAL_UARTEx_SetRxFifoThreshold(&huart1, UART_RXFIFO_THRESHOLD_1_8) != HAL_OK)
  {
    Error_Handler();
  }
  if (HAL_UARTEx_DisableFifoMode(&huart1) != HAL_OK)
  {
    Error_Handler();
  }

}

static void MX_USART2_UART_Init(void)
{

  huart2.Instance = USART2;
  huart2.Init.BaudRate = 115200;
  huart2.Init.WordLength = UART_WORDLENGTH_8B;
  huart2.Init.StopBits = UART_STOPBITS_1;
  huart2.Init.Parity = UART_PARITY_NONE;
  huart2.Init.Mode = UART_MODE_TX_RX;
  huart2.Init.HwFlowCtl = UART_HWCONTROL_NONE;
  huart2.Init.OverSampling = UART_OVERSAMPLING_16;
  huart2.Init.OneBitSampling = UART_ONE_BIT_SAMPLE_DISABLE;
  huart2.Init.ClockPrescaler = UART_PRESCALER_DIV1;
  huart2.AdvancedInit.AdvFeatureInit = UART_ADVFEATURE_NO_INIT;
  if (HAL_UART_Init(&huart2) != HAL_OK)
  {
    Error_Handler();
  }
  if (HAL_UARTEx_SetTxFifoThreshold(&huart2, UART_TXFIFO_THRESHOLD_1_8) != HAL_OK)
  {
    Error_Handler();
  }
  if (HAL_UARTEx_SetRxFifoThreshold(&huart2, UART_RXFIFO_THRESHOLD_1_8) != HAL_OK)
  {
    Error_Handler();
  }
  if (HAL_UARTEx_DisableFifoMode(&huart2) != HAL_OK)
  {
    Error_Handler();
  }

}

static void MX_USART3_UART_Init(void)
{

  huart3.Instance = USART3;
  huart3.Init.BaudRate = 115200;
  huart3.Init.WordLength = UART_WORDLENGTH_8B;
  huart3.Init.StopBits = UART_STOPBITS_1;
  huart3.Init.Parity = UART_PARITY_NONE;
  huart3.Init.Mode = UART_MODE_TX_RX;
  huart3.Init.HwFlowCtl = UART_HWCONTROL_NONE;
  huart3.Init.OverSampling = UART_OVERSAMPLING_16;
  huart3.Init.OneBitSampling = UART_ONE_BIT_SAMPLE_DISABLE;
  huart3.Init.ClockPrescaler = UART_PRESCALER_DIV1;
  huart3.AdvancedInit.AdvFeatureInit = UART_ADVFEATURE_NO_INIT;
  if (HAL_UART_Init(&huart3) != HAL_OK)
  {
    Error_Handler();
  }
  if (HAL_UARTEx_SetTxFifoThreshold(&huart3, UART_TXFIFO_THRESHOLD_1_8) != HAL_OK)
  {
    Error_Handler();
  }
  if (HAL_UARTEx_SetRxFifoThreshold(&huart3, UART_RXFIFO_THRESHOLD_1_8) != HAL_OK)
  {
    Error_Handler();
  }
  if (HAL_UARTEx_DisableFifoMode(&huart3) != HAL_OK)
  {
    Error_Handler();
  }

}

static void MX_DMA_Init(void)
{

  /* DMA controller clock enable */
  __HAL_RCC_DMA1_CLK_ENABLE();
  __HAL_RCC_DMA2_CLK_ENABLE();

  /* DMA interrupt init */
  /* DMA1_Stream0_IRQn interrupt configuration */
  HAL_NVIC_SetPriority(DMA1_Stream0_IRQn, 5, 0);
  HAL_NVIC_EnableIRQ(DMA1_Stream0_IRQn);
  /* DMA1_Stream1_IRQn interrupt configuration */
  HAL_NVIC_SetPriority(DMA1_Stream1_IRQn, 5, 0);
  HAL_NVIC_EnableIRQ(DMA1_Stream1_IRQn);
  /* DMA1_Stream2_IRQn interrupt configuration */
  HAL_NVIC_SetPriority(DMA1_Stream2_IRQn, 5, 0);
  HAL_NVIC_EnableIRQ(DMA1_Stream2_IRQn);
  /* DMA1_Stream3_IRQn interrupt configuration */
  HAL_NVIC_SetPriority(DMA1_Stream3_IRQn, 5, 0);
  HAL_NVIC_EnableIRQ(DMA1_Stream3_IRQn);
  /* DMA1_Stream5_IRQn interrupt configuration */
  HAL_NVIC_SetPriority(DMA1_Stream5_IRQn, 5, 0);
  HAL_NVIC_EnableIRQ(DMA1_Stream5_IRQn);
  /* DMA1_Stream6_IRQn interrupt configuration */
  HAL_NVIC_SetPriority(DMA1_Stream6_IRQn, 5, 0);
  HAL_NVIC_EnableIRQ(DMA1_Stream6_IRQn);
  /* DMA1_Stream7_IRQn interrupt configuration */
  HAL_NVIC_SetPriority(DMA1_Stream7_IRQn, 0, 0);
  HAL_NVIC_EnableIRQ(DMA1_Stream7_IRQn);
  /* DMA2_Stream0_IRQn interrupt configuration */
  HAL_NVIC_SetPriority(DMA2_Stream0_IRQn, 0, 0);
  HAL_NVIC_EnableIRQ(DMA2_Stream0_IRQn);
  /* DMA2_Stream1_IRQn interrupt configuration */
  HAL_NVIC_SetPriority(DMA2_Stream1_IRQn, 0, 0);
  HAL_NVIC_EnableIRQ(DMA2_Stream1_IRQn);
  /* DMA2_Stream4_IRQn interrupt configuration */
  HAL_NVIC_SetPriority(DMA2_Stream4_IRQn, 5, 0);
  HAL_NVIC_EnableIRQ(DMA2_Stream4_IRQn);

}

static void MX_GPIO_Init(void)
{
  GPIO_InitTypeDef GPIO_InitStruct = {0};

  /* GPIO Ports Clock Enable */
  __HAL_RCC_GPIOE_CLK_ENABLE();
  __HAL_RCC_GPIOC_CLK_ENABLE();
  __HAL_RCC_GPIOH_CLK_ENABLE();
  __HAL_RCC_GPIOA_CLK_ENABLE();
  __HAL_RCC_GPIOB_CLK_ENABLE();
  __HAL_RCC_GPIOD_CLK_ENABLE();

  /*Configure GPIO pin Output Level */
  HAL_GPIO_WritePin(GPIOE, SPI4_CS_Pin|CAMERA_Pin, GPIO_PIN_RESET);

  /*Configure GPIO pin Output Level */
  HAL_GPIO_WritePin(PW_HOLD_GPIO_Port, PW_HOLD_Pin, GPIO_PIN_RESET);

  /*Configure GPIO pin Output Level */
  HAL_GPIO_WritePin(GPIOD, LED3_Pin|LED4_Pin|LED1_Pin|LED2_Pin, GPIO_PIN_RESET);

  /*Configure GPIO pins : SPI4_CS_Pin CAMERA_Pin */
  GPIO_InitStruct.Pin = SPI4_CS_Pin|CAMERA_Pin;
  GPIO_InitStruct.Mode = GPIO_MODE_OUTPUT_PP;
  GPIO_InitStruct.Pull = GPIO_NOPULL;
  GPIO_InitStruct.Speed = GPIO_SPEED_FREQ_LOW;
  HAL_GPIO_Init(GPIOE, &GPIO_InitStruct);

  /*Configure GPIO pin : SD_DET_Pin */
  GPIO_InitStruct.Pin = SD_DET_Pin;
  GPIO_InitStruct.Mode = GPIO_MODE_INPUT;
  GPIO_InitStruct.Pull = GPIO_NOPULL;
  HAL_GPIO_Init(SD_DET_GPIO_Port, &GPIO_InitStruct);

  /*Configure GPIO pin : PW_HOLD_Pin */
  GPIO_InitStruct.Pin = PW_HOLD_Pin;
  GPIO_InitStruct.Mode = GPIO_MODE_OUTPUT_PP;
  GPIO_InitStruct.Pull = GPIO_NOPULL;
  GPIO_InitStruct.Speed = GPIO_SPEED_FREQ_LOW;
  HAL_GPIO_Init(PW_HOLD_GPIO_Port, &GPIO_InitStruct);

  /*Configure GPIO pins : LED3_Pin LED4_Pin LED1_Pin LED2_Pin */
  GPIO_InitStruct.Pin = LED3_Pin|LED4_Pin|LED1_Pin|LED2_Pin;
  GPIO_InitStruct.Mode = GPIO_MODE_OUTPUT_PP;
  GPIO_InitStruct.Pull = GPIO_NOPULL;
  GPIO_InitStruct.Speed = GPIO_SPEED_FREQ_LOW;
  HAL_GPIO_Init(GPIOD, &GPIO_InitStruct);

}

void StartDefaultTask(void *argument)
{
  /* init code for USB_DEVICE */
//  MX_USB_DEVICE_Init();
  /* USER CODE BEGIN 5 */
  /* Infinite loop */

  for (;;) {
    osDelay(1000);
  }
  /* USER CODE END 5 */
}

void HAL_TIM_PeriodElapsedCallback(TIM_HandleTypeDef *htim)
{
  if (htim->Instance == TIM1) {
    HAL_IncTick();
  }
}

void Error_Handler(void)
{
}

#ifdef  USE_FULL_ASSERT
/**
  * @brief  Reports the name of the source file and the source line number
  *         where the assert_param error has occurred.
  * @param  file: pointer to the source file name
  * @param  line: assert_param error line source number
  * @retval None
  */
void assert_failed(uint8_t *file, uint32_t line)
{
  /* USER CODE BEGIN 6 */
  /* User can add his own implementation to report the file name and line
     number,
     tex: printf("Wrong parameters value: file %s on line %d\r\n", file, line)
   */
  /* USER CODE END 6 */
}
#endif /* USE_FULL_ASSERT */

/************************ (C) COPYRIGHT STMicroelectronics *****END OF FILE****/
